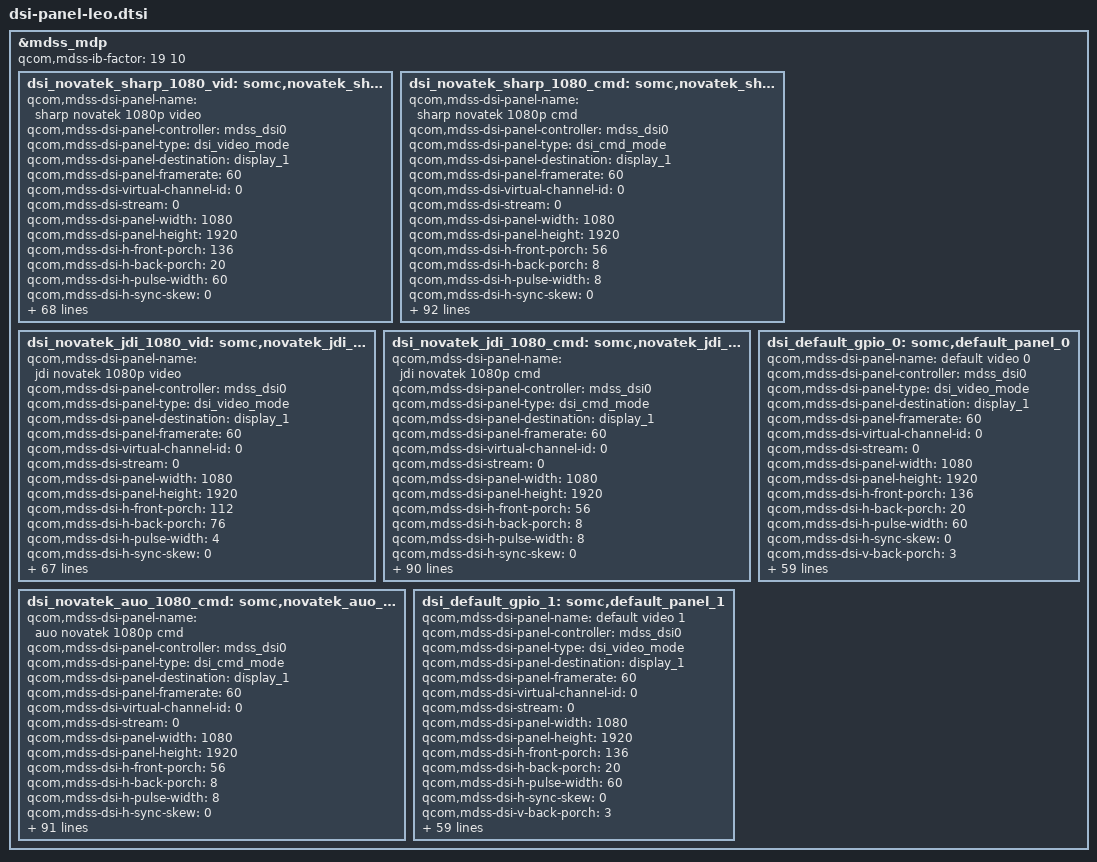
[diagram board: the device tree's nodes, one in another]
/* Copyright (c) 2012, Code Aurora Forum. All rights reserved.
 * Copyright (c) 2014 Sony Mobile Communications Inc.
 *
 * This program is free software; you can redistribute it and/or modify
 * it under the terms of the GNU General Public License version 2 and
 * only version 2 as published by the Free Software Foundation.
 *
 * This program is distributed in the hope that it will be useful,
 * but WITHOUT ANY WARRANTY; without even the implied warranty of
 * MERCHANTABILITY or FITNESS FOR A PARTICULAR PURPOSE.  See the
 * GNU General Public License for more details.
 */

&mdss_mdp {
	qcom,mdss-ib-factor = <19 10>;
	dsi_novatek_sharp_1080_vid: somc,novatek_sharp_1080p_video_panel {
		qcom,mdss-dsi-panel-name = "sharp novatek 1080p video";
		qcom,mdss-dsi-panel-controller = <&mdss_dsi0>;
		qcom,mdss-dsi-panel-type = "dsi_video_mode";
		qcom,mdss-dsi-panel-destination = "display_1";
		qcom,mdss-dsi-panel-framerate = <60>;
		qcom,mdss-dsi-virtual-channel-id = <0>;
		qcom,mdss-dsi-stream = <0>;
		qcom,mdss-dsi-panel-width = <1080>;
		qcom,mdss-dsi-panel-height = <1920>;
		qcom,mdss-dsi-h-front-porch = <136>;
		qcom,mdss-dsi-h-back-porch = <20>;
		qcom,mdss-dsi-h-pulse-width = <60>;
		qcom,mdss-dsi-h-sync-skew = <0>;
		qcom,mdss-dsi-v-back-porch = <3>;
		qcom,mdss-dsi-v-front-porch = <4>;
		qcom,mdss-dsi-v-pulse-width = <2>;
		qcom,mdss-dsi-h-left-border = <0>;
		qcom,mdss-dsi-h-right-border = <0>;
		qcom,mdss-dsi-v-top-border = <0>;
		qcom,mdss-dsi-v-bottom-border = <0>;
		qcom,mdss-dsi-bpp = <24>;
		qcom,mdss-dsi-underflow-color = <0x0>;
		qcom,mdss-dsi-border-color = <0>;
		somc,mdss-dsi-init-command = [15 01 00 00 00 00 02 BB 03
				39 01 00 00 00 00 06 3B 03 05 04 50 88
				15 01 00 00 00 00 02 FF 24
				15 01 00 00 00 00 02 FB 01
				15 01 00 00 00 00 02 C4 9A
				15 01 00 00 00 00 02 FF 10];
		qcom,mdss-dsi-on-command = [05 01 00 00 96 00 01 11
				05 01 00 00 28 00 01 29];
		qcom,mdss-dsi-off-command = [15 01 00 00 00 00 02 FF 10
				05 01 00 00 14 00 01 28
				05 01 00 00 50 00 01 10];
		qcom,mdss-dsi-on-command-state = "dsi_lp_mode";
		qcom,mdss-dsi-off-command-state = "dsi_hs_mode";
		qcom,mdss-dsi-h-sync-pulse = <1>;
		qcom,mdss-dsi-traffic-mode = "non_burst_sync_event";
		qcom,mdss-dsi-bllp-eof-power-mode;
		qcom,mdss-dsi-bllp-power-mode;
		qcom,mdss-dsi-lane-0-state;
		qcom,mdss-dsi-lane-1-state;
		qcom,mdss-dsi-lane-2-state;
		qcom,mdss-dsi-lane-3-state;
		qcom,mdss-dsi-panel-timings = [E6 38 26 00 68 6E 2A 3C 2C 03 04 00];
		qcom,mdss-dsi-lp11-init;
		qcom,mdss-dsi-t-clk-post = <0x02>;
		qcom,mdss-dsi-t-clk-pre = <0x2B>;
		qcom,mdss-dsi-bl-min-level = <1>;
		qcom,mdss-dsi-bl-max-level = <4095>;
		qcom,mdss-brightness-max-level = <4095>;
		qcom,mdss-dsi-dma-trigger = "trigger_sw";
		qcom,mdss-dsi-mdp-trigger = "none";
		qcom,mdss-dsi-bl-pmic-control-type = "bl_ctrl_wled";
		qcom,mdss-dsi-pan-enable-dynamic-fps;
		qcom,mdss-dsi-pan-fps-update = "dfps_suspend_resume_mode";
		qcom,cont-splash-enabled;

		somc,driver-ic = <0>;
		somc,dric-gpio = <&msmgpio 26 0>;
		somc,touch-reset-gpio = <&msmgpio 85 0>;
		somc,mul-channel-scaling = <3>;
		somc,mdss-phy-size-mm = <64 114>;
		somc,mdss-dsi-lane-config = [00 c2 ef 00 00 00 00 01 ff
				00 c2 ef 00 00 00 00 01 ff
				00 c2 ef 00 00 00 00 01 ff
				00 c2 ef 00 00 00 00 01 ff
				00 02 45 00 00 00 00 01 97];
		somc,mdss-dsi-disp-on-in-hs = <1>;
		somc,mdss-dsi-wait-time-before-on-cmd = <150>;
		somc,lcd-id = <1>;
		somc,lcd-id-adc = <215000 256000>;
		somc,disp-en-on-pre = <200>;
		somc,disp-en-on-post = <10>;
		somc,pw-on-rst-seq = <1 1>, <0 1>, <1 20>;
		somc,disp-en-off-post = <200>;
		somc,pw-off-rst-seq = <0 5>;
		somc,pw-down-period = <100>;

		somc,mdss-dsi-pre-uv-command = [23 01 00 00 00 00 02 B0 04];
		somc,mdss-dsi-uv-command = [06 01 00 00 00 00 01 DA
			06 01 00 00 00 00 01 DB];
		somc,mdss-dsi-uv-param-type = <4>;
		somc,mdss-dsi-pcc-table-size = <225>;
		somc,mdss-dsi-pcc-table = <
			0x00 0x01 0x38 0x3B 0x38 0x3B 0x5700 0x7000 0x8000
			0x00 0x02 0x34 0x37 0x38 0x3B 0x5900 0x6f00 0x8000
			0x00 0x03 0x30 0x33 0x38 0x3B 0x5c00 0x6e00 0x8000
			0x00 0x04 0x2C 0x2F 0x38 0x3B 0x5d80 0x6c80 0x8000
			0x00 0x05 0x28 0x2B 0x38 0x3B 0x6080 0x6c80 0x8000
			0x00 0x06 0x24 0x27 0x38 0x3B 0x6380 0x6c80 0x8000
			0x00 0x07 0x20 0x23 0x38 0x3B 0x6700 0x6c00 0x8000
			0x00 0x08 0x1C 0x1F 0x38 0x3B 0x6980 0x6b00 0x8000
			0x00 0x09 0x18 0x1B 0x38 0x3B 0x6d00 0x6a80 0x8000
			0x00 0x0A 0x14 0x17 0x38 0x3B 0x7180 0x6900 0x8000
			0x00 0x0B 0x10 0x13 0x38 0x3B 0x7800 0x6800 0x8000
			0x00 0x0C 0x0C 0x0F 0x38 0x3B 0x7d00 0x6700 0x8000
			0x00 0x0D 0x08 0x0B 0x38 0x3B 0x8000 0x6500 0x7d00
			0x00 0x0E 0x04 0x07 0x38 0x3B 0x8000 0x6000 0x7700
			0x00 0x0F 0x00 0x03 0x38 0x3B 0x8000 0x5900 0x7000
			0x00 0x10 0x38 0x3B 0x34 0x37 0x5900 0x7280 0x8000
			0x00 0x11 0x34 0x37 0x34 0x37 0x5b00 0x7100 0x8000
			0x00 0x12 0x30 0x33 0x34 0x37 0x5e00 0x7180 0x8000
			0x00 0x13 0x2C 0x2F 0x34 0x37 0x6080 0x7180 0x8000
			0x00 0x14 0x28 0x2B 0x34 0x37 0x6400 0x7000 0x8000
			0x00 0x15 0x24 0x27 0x34 0x37 0x6700 0x7000 0x8000
			0x00 0x16 0x20 0x23 0x34 0x37 0x6900 0x6f00 0x8000
			0x00 0x17 0x1C 0x1F 0x34 0x37 0x6c00 0x6e80 0x8000
			0x00 0x18 0x18 0x1B 0x34 0x37 0x7000 0x6d80 0x8000
			0x00 0x19 0x14 0x17 0x34 0x37 0x7580 0x6b80 0x8000
			0x00 0x1A 0x10 0x13 0x34 0x37 0x7b00 0x6a80 0x8000
			0x00 0x1B 0x0C 0x0F 0x34 0x37 0x8000 0x6a80 0x8000
			0x00 0x1C 0x08 0x0B 0x34 0x37 0x8000 0x6600 0x7c00
			0x00 0x1D 0x04 0x07 0x34 0x37 0x8000 0x6100 0x7400
			0x00 0x1E 0x00 0x03 0x34 0x37 0x8000 0x5b00 0x6e00
			0x00 0x1F 0x38 0x3B 0x30 0x33 0x5c80 0x7600 0x8000
			0x00 0x20 0x34 0x37 0x30 0x33 0x5e00 0x7500 0x8000
			0x00 0x21 0x30 0x33 0x30 0x33 0x6100 0x7480 0x8000
			0x00 0x22 0x2C 0x2F 0x30 0x33 0x6400 0x7400 0x8000
			0x00 0x23 0x28 0x2B 0x30 0x33 0x6500 0x7300 0x8000
			0x00 0x24 0x24 0x27 0x30 0x33 0x6880 0x7400 0x8000
			0x00 0x25 0x20 0x23 0x30 0x33 0x6b00 0x7200 0x8000
			0x00 0x26 0x1C 0x1F 0x30 0x33 0x6e00 0x6f00 0x8000
			0x00 0x27 0x18 0x1B 0x30 0x33 0x7300 0x7080 0x8000
			0x00 0x28 0x14 0x17 0x30 0x33 0x7700 0x6d80 0x8000
			0x00 0x29 0x10 0x13 0x30 0x33 0x7c00 0x6d80 0x8000
			0x00 0x2A 0x0C 0x0F 0x30 0x33 0x8000 0x6c00 0x7e00
			0x00 0x2B 0x08 0x0B 0x30 0x33 0x8000 0x6700 0x7a00
			0x00 0x2C 0x04 0x07 0x30 0x33 0x8000 0x6100 0x7200
			0x00 0x2D 0x00 0x03 0x30 0x33 0x8000 0x5b00 0x6c00
			0x00 0x2E 0x38 0x3B 0x2C 0x2F 0x5c00 0x7880 0x8000
			0x00 0x2F 0x34 0x37 0x2C 0x2F 0x5f00 0x7700 0x8000
			0x00 0x30 0x30 0x33 0x2C 0x2F 0x6100 0x7700 0x8000
			0x00 0x31 0x2C 0x2F 0x2C 0x2F 0x6500 0x7680 0x8000
			0x00 0x32 0x28 0x2B 0x2C 0x2F 0x6700 0x7600 0x8000
			0x00 0x33 0x24 0x27 0x2C 0x2F 0x6a00 0x7500 0x8000
			0x00 0x34 0x20 0x23 0x2C 0x2F 0x6e00 0x7500 0x8000
			0x00 0x35 0x1C 0x1F 0x2C 0x2F 0x7180 0x7400 0x8000
			0x00 0x36 0x18 0x1B 0x2C 0x2F 0x7580 0x7300 0x8000
			0x00 0x37 0x14 0x17 0x2C 0x2F 0x7b00 0x7080 0x8000
			0x00 0x38 0x10 0x13 0x2C 0x2F 0x8000 0x7080 0x7f00
			0x00 0x39 0x0C 0x0F 0x2C 0x2F 0x8000 0x6b00 0x7a00
			0x00 0x3A 0x08 0x0B 0x2C 0x2F 0x8000 0x6500 0x7400
			0x00 0x3B 0x04 0x07 0x2C 0x2F 0x8000 0x6000 0x6d00
			0x00 0x3C 0x00 0x03 0x2C 0x2F 0x8000 0x5a00 0x6800
			0x00 0x3D 0x38 0x3B 0x28 0x2B 0x6000 0x7c00 0x8000
			0x00 0x3E 0x34 0x37 0x28 0x2B 0x6200 0x7b00 0x8000
			0x00 0x3F 0x30 0x33 0x28 0x2B 0x6600 0x7b00 0x8000
			0x00 0x40 0x2C 0x2F 0x28 0x2B 0x6900 0x7c00 0x8000
			0x00 0x41 0x28 0x2B 0x28 0x2B 0x6b80 0x7900 0x8000
			0x00 0x42 0x24 0x27 0x28 0x2B 0x6e00 0x7900 0x8000
			0x00 0x43 0x20 0x23 0x28 0x2B 0x7100 0x7780 0x8000
			0x00 0x44 0x1C 0x1F 0x28 0x2B 0x7500 0x7700 0x8000
			0x00 0x45 0x18 0x1B 0x28 0x2B 0x7a00 0x7600 0x8000
			0x00 0x46 0x14 0x17 0x28 0x2B 0x8000 0x7500 0x8000
			0x00 0x47 0x10 0x13 0x28 0x2B 0x8000 0x7000 0x7c00
			0x00 0x48 0x0C 0x0F 0x28 0x2B 0x8000 0x6b00 0x7800
			0x00 0x49 0x08 0x0B 0x28 0x2B 0x8000 0x6600 0x7200
			0x00 0x4A 0x04 0x07 0x28 0x2B 0x8000 0x6000 0x6c00
			0x00 0x4B 0x00 0x03 0x28 0x2B 0x8000 0x5900 0x6500
			0x00 0x4C 0x38 0x3B 0x24 0x27 0x6200 0x8000 0x8000
			0x00 0x4D 0x34 0x37 0x24 0x27 0x6500 0x7f00 0x8000
			0x00 0x4E 0x30 0x33 0x24 0x27 0x6800 0x7f00 0x8000
			0x00 0x4F 0x2C 0x2F 0x24 0x27 0x6b00 0x7e00 0x8000
			0x00 0x50 0x28 0x2B 0x24 0x27 0x6e00 0x7c80 0x8000
			0x00 0x51 0x24 0x27 0x24 0x27 0x7200 0x7d00 0x8000
			0x00 0x52 0x20 0x23 0x24 0x27 0x7500 0x7a00 0x8000
			0x00 0x53 0x1C 0x1F 0x24 0x27 0x7900 0x7a00 0x8000
			0x00 0x54 0x18 0x1B 0x24 0x27 0x7e00 0x7a00 0x8000
			0x00 0x55 0x14 0x17 0x24 0x27 0x8000 0x7300 0x7c00
			0x00 0x56 0x10 0x13 0x24 0x27 0x8000 0x6e00 0x7800
			0x00 0x57 0x0C 0x0F 0x24 0x27 0x8000 0x6900 0x7300
			0x00 0x58 0x08 0x0B 0x24 0x27 0x8000 0x6400 0x6d00
			0x00 0x59 0x04 0x07 0x24 0x27 0x8000 0x5e00 0x6800
			0x00 0x5A 0x00 0x03 0x24 0x27 0x8000 0x5900 0x6300
			0x00 0x5B 0x38 0x3B 0x20 0x23 0x6200 0x8000 0x7d00
			0x00 0x5C 0x34 0x37 0x20 0x23 0x6600 0x8000 0x7e00
			0x00 0x5D 0x30 0x33 0x20 0x23 0x6a00 0x8000 0x7f00
			0x00 0x5E 0x2C 0x2F 0x20 0x23 0x6d00 0x8000 0x7f00
			0x00 0x5F 0x28 0x2B 0x20 0x23 0x7100 0x8000 0x8000
			0x00 0x60 0x24 0x27 0x20 0x23 0x7400 0x7f00 0x8000
			0x00 0x61 0x20 0x23 0x20 0x23 0x7700 0x7e80 0x8000
			0x00 0x62 0x1C 0x1F 0x20 0x23 0x7b00 0x7d00 0x8000
			0x00 0x63 0x18 0x1B 0x20 0x23 0x7f00 0x7c00 0x8000
			0x00 0x64 0x14 0x17 0x20 0x23 0x8000 0x7500 0x7b00
			0x00 0x65 0x10 0x13 0x20 0x23 0x8000 0x7000 0x7600
			0x00 0x66 0x0C 0x0F 0x20 0x23 0x8000 0x6a00 0x7100
			0x00 0x67 0x08 0x0B 0x20 0x23 0x8000 0x6400 0x6b00
			0x00 0x68 0x04 0x07 0x20 0x23 0x8000 0x5e00 0x6600
			0x00 0x69 0x00 0x03 0x20 0x23 0x8000 0x5800 0x6000
			0x00 0x6A 0x38 0x3B 0x1C 0x1F 0x6300 0x8000 0x7a00
			0x00 0x6B 0x34 0x37 0x1C 0x1F 0x6600 0x8000 0x7b00
			0x00 0x6C 0x30 0x33 0x1C 0x1F 0x6a00 0x8000 0x7c00
			0x00 0x6D 0x2C 0x2F 0x1C 0x1F 0x6e00 0x8000 0x7d00
			0x00 0x6E 0x28 0x2B 0x1C 0x1F 0x7200 0x8000 0x7e00
			0x00 0x6F 0x24 0x27 0x1C 0x1F 0x7600 0x8000 0x7e00
			0x00 0x70 0x20 0x23 0x1C 0x1F 0x7a00 0x8000 0x7f00
			0x00 0x71 0x18 0x1B 0x1C 0x1F 0x8000 0x7c00 0x7c00
			0x00 0x72 0x14 0x17 0x1C 0x1F 0x8000 0x7400 0x7780
			0x00 0x73 0x10 0x13 0x1C 0x1F 0x8000 0x6f00 0x7300
			0x00 0x74 0x0C 0x0F 0x1C 0x1F 0x8000 0x6900 0x6e00
			0x00 0x75 0x08 0x0B 0x1C 0x1F 0x8000 0x6300 0x6800
			0x00 0x76 0x04 0x07 0x1C 0x1F 0x8000 0x5d00 0x6280
			0x00 0x77 0x00 0x03 0x1C 0x1F 0x8000 0x5800 0x5d00
			0x00 0x78 0x38 0x3B 0x18 0x1B 0x6300 0x8000 0x7800
			0x00 0x79 0x34 0x37 0x18 0x1B 0x6700 0x8000 0x7900
			0x00 0x7A 0x30 0x33 0x18 0x1B 0x6a00 0x8000 0x7900
			0x00 0x7B 0x2C 0x2F 0x18 0x1B 0x6e00 0x8000 0x7b00
			0x00 0x7C 0x28 0x2B 0x18 0x1B 0x7180 0x8000 0x7c00
			0x00 0x7D 0x24 0x27 0x18 0x1B 0x7500 0x8000 0x7b00
			0x00 0x7E 0x20 0x23 0x18 0x1B 0x7a00 0x8000 0x7c80
			0x00 0x7F 0x1C 0x1F 0x18 0x1B 0x8000 0x8000 0x7e00
			0x00 0x80 0x18 0x1B 0x18 0x1B 0x8000 0x7a00 0x7900
			0x00 0x81 0x14 0x17 0x18 0x1B 0x8000 0x7400 0x7500
			0x00 0x82 0x10 0x13 0x18 0x1B 0x8000 0x6e00 0x6f00
			0x00 0x83 0x0C 0x0F 0x18 0x1B 0x8000 0x6900 0x6b00
			0x00 0x84 0x08 0x0B 0x18 0x1B 0x8000 0x6200 0x6500
			0x00 0x85 0x04 0x07 0x18 0x1B 0x8000 0x5d00 0x6000
			0x00 0x86 0x00 0x03 0x18 0x1B 0x8000 0x5700 0x5b00
			0x00 0x87 0x38 0x3B 0x14 0x17 0x6300 0x8000 0x7580
			0x00 0x88 0x34 0x37 0x14 0x17 0x6700 0x8000 0x7680
			0x00 0x89 0x30 0x33 0x14 0x17 0x6a00 0x8000 0x7780
			0x00 0x8A 0x2C 0x2F 0x14 0x17 0x6d00 0x8000 0x7800
			0x00 0x8B 0x28 0x2B 0x14 0x17 0x7100 0x8000 0x7800
			0x00 0x8C 0x24 0x27 0x14 0x17 0x7500 0x8000 0x7980
			0x00 0x8D 0x20 0x23 0x14 0x17 0x7a00 0x8000 0x7a00
			0x00 0x8E 0x1C 0x1F 0x14 0x17 0x7f00 0x8000 0x7a80
			0x00 0x8F 0x18 0x1B 0x14 0x17 0x8000 0x7b00 0x7700
			0x00 0x90 0x14 0x17 0x14 0x17 0x8000 0x7300 0x7100
			0x00 0x91 0x10 0x13 0x14 0x17 0x8000 0x6d00 0x6d00
			0x00 0x92 0x0C 0x0F 0x14 0x17 0x8000 0x6800 0x6900
			0x00 0x93 0x08 0x0B 0x14 0x17 0x8000 0x6200 0x6300
			0x00 0x94 0x04 0x07 0x14 0x17 0x8000 0x5c00 0x5d00
			0x00 0x95 0x00 0x03 0x14 0x17 0x8000 0x5600 0x5900
			0x00 0x96 0x38 0x3B 0x10 0x13 0x6300 0x8000 0x7300
			0x00 0x97 0x34 0x37 0x10 0x13 0x6600 0x8000 0x7400
			0x00 0x98 0x30 0x33 0x10 0x13 0x6a00 0x8000 0x7500
			0x00 0x99 0x2C 0x2F 0x10 0x13 0x6e00 0x8000 0x7600
			0x00 0x9A 0x28 0x2B 0x10 0x13 0x7100 0x8000 0x7600
			0x00 0x9B 0x24 0x27 0x10 0x13 0x7500 0x8000 0x7700
			0x00 0x9C 0x20 0x23 0x10 0x13 0x7980 0x8000 0x7800
			0x00 0x9D 0x1C 0x1F 0x10 0x13 0x7f00 0x8000 0x7800
			0x00 0x9E 0x18 0x1B 0x10 0x13 0x8000 0x7b00 0x7500
			0x00 0x9F 0x14 0x17 0x10 0x13 0x8000 0x7300 0x6f00
			0x00 0xA0 0x10 0x13 0x10 0x13 0x8000 0x6d00 0x6b00
			0x00 0xA1 0x0C 0x0F 0x10 0x13 0x8000 0x6800 0x6600
			0x00 0xA2 0x08 0x0B 0x10 0x13 0x8000 0x6200 0x6000
			0x00 0xA3 0x04 0x07 0x10 0x13 0x8000 0x5b00 0x5b00
			0x00 0xA4 0x00 0x03 0x10 0x13 0x8000 0x5600 0x5700
			0x00 0xA5 0x38 0x3B 0x0C 0x0F 0x6200 0x8000 0x7000
			0x00 0xA6 0x34 0x37 0x0C 0x0F 0x6700 0x8000 0x7100
			0x00 0xA7 0x30 0x33 0x0C 0x0F 0x6a00 0x8000 0x7200
			0x00 0xA8 0x2C 0x2F 0x0C 0x0F 0x6d00 0x8000 0x7300
			0x00 0xA9 0x28 0x2B 0x0C 0x0F 0x7100 0x8000 0x7400
			0x00 0xAA 0x24 0x27 0x0C 0x0F 0x7500 0x8000 0x7480
			0x00 0xAB 0x20 0x23 0x0C 0x0F 0x7900 0x8000 0x7500
			0x00 0xAC 0x1C 0x1F 0x0C 0x0F 0x7f00 0x8000 0x7600
			0x00 0xAD 0x18 0x1B 0x0C 0x0F 0x8000 0x7b00 0x7200
			0x00 0xAE 0x14 0x17 0x0C 0x0F 0x8000 0x7300 0x6d00
			0x00 0xAF 0x10 0x13 0x0C 0x0F 0x8000 0x6d00 0x6800
			0x00 0xB0 0x0C 0x0F 0x0C 0x0F 0x8000 0x6800 0x6400
			0x00 0xB1 0x08 0x0B 0x0C 0x0F 0x8000 0x6100 0x5d00
			0x00 0xB2 0x04 0x07 0x0C 0x0F 0x8000 0x5b00 0x5900
			0x00 0xB3 0x00 0x03 0x0C 0x0F 0x8000 0x5600 0x5480
			0x00 0xB4 0x38 0x3B 0x08 0x0B 0x6200 0x8000 0x6e00
			0x00 0xB5 0x34 0x37 0x08 0x0B 0x6600 0x8000 0x6e00
			0x00 0xB6 0x30 0x33 0x08 0x0B 0x6900 0x8000 0x6f00
			0x00 0xB7 0x2C 0x2F 0x08 0x0B 0x6d00 0x8000 0x7000
			0x00 0xB8 0x28 0x2B 0x08 0x0B 0x7100 0x8000 0x7200
			0x00 0xB9 0x24 0x27 0x08 0x0B 0x7500 0x8000 0x7200
			0x00 0xBA 0x20 0x23 0x08 0x0B 0x7a00 0x8000 0x7200
			0x00 0xBB 0x1C 0x1F 0x08 0x0B 0x7f00 0x8000 0x7300
			0x00 0xBC 0x18 0x1B 0x08 0x0B 0x8000 0x7b00 0x7000
			0x00 0xBD 0x14 0x17 0x08 0x0B 0x8000 0x7200 0x6a00
			0x00 0xBE 0x10 0x13 0x08 0x0B 0x8000 0x6c00 0x6500
			0x00 0xBF 0x0C 0x0F 0x08 0x0B 0x8000 0x6600 0x6000
			0x00 0xC0 0x08 0x0B 0x08 0x0B 0x8000 0x6000 0x5b00
			0x00 0xC1 0x04 0x07 0x08 0x0B 0x8000 0x5b00 0x5700
			0x00 0xC2 0x00 0x03 0x08 0x0B 0x8000 0x5500 0x5100
			0x00 0xC3 0x38 0x3B 0x04 0x07 0x6200 0x8000 0x6b00
			0x00 0xC4 0x34 0x37 0x04 0x07 0x6500 0x8000 0x6c00
			0x00 0xC5 0x30 0x33 0x04 0x07 0x6800 0x8000 0x6d80
			0x00 0xC6 0x2C 0x2F 0x04 0x07 0x6c00 0x8000 0x6e00
			0x00 0xC7 0x28 0x2B 0x04 0x07 0x7000 0x8000 0x6e00
			0x00 0xC8 0x24 0x27 0x04 0x07 0x7400 0x8000 0x6f00
			0x00 0xC9 0x20 0x23 0x04 0x07 0x7800 0x8000 0x7000
			0x00 0xCA 0x1C 0x1F 0x04 0x07 0x7e00 0x8000 0x7000
			0x00 0xCB 0x18 0x1B 0x04 0x07 0x8000 0x7a80 0x6b80
			0x00 0xCC 0x14 0x17 0x04 0x07 0x8000 0x7400 0x6780
			0x00 0xCD 0x10 0x13 0x04 0x07 0x8000 0x6e00 0x6380
			0x00 0xCE 0x0C 0x0F 0x04 0x07 0x8000 0x6700 0x5e00
			0x00 0xCF 0x08 0x0B 0x04 0x07 0x8000 0x6180 0x5980
			0x00 0xD0 0x04 0x07 0x04 0x07 0x8000 0x5b00 0x5500
			0x00 0xD1 0x00 0x03 0x04 0x07 0x8000 0x5500 0x5100
			0x00 0xD2 0x38 0x3B 0x00 0x03 0x6100 0x8000 0x6900
			0x00 0xD3 0x34 0x37 0x00 0x03 0x6400 0x8000 0x6a00
			0x00 0xD4 0x30 0x33 0x00 0x03 0x6800 0x8000 0x6b00
			0x00 0xD5 0x2C 0x2F 0x00 0x03 0x6c00 0x8000 0x6b80
			0x00 0xD6 0x28 0x2B 0x00 0x03 0x6f00 0x8000 0x6c00
			0x00 0xD7 0x24 0x27 0x00 0x03 0x7300 0x8000 0x6d00
			0x00 0xD8 0x20 0x23 0x00 0x03 0x7900 0x8000 0x6d00
			0x00 0xD9 0x1C 0x1F 0x00 0x03 0x7f00 0x8000 0x6e00
			0x00 0xDA 0x18 0x1B 0x00 0x03 0x8000 0x7b00 0x6a80
			0x00 0xDB 0x14 0x17 0x00 0x03 0x8000 0x7400 0x6580
			0x00 0xDC 0x10 0x13 0x00 0x03 0x8000 0x6d00 0x6180
			0x00 0xDD 0x0C 0x0F 0x00 0x03 0x8000 0x6900 0x5e00
			0x00 0xDE 0x08 0x0B 0x00 0x03 0x8000 0x6200 0x5800
			0x00 0xDF 0x04 0x07 0x00 0x03 0x8000 0x5a00 0x5200
			0x00 0xE0 0x00 0x03 0x00 0x03 0x8000 0x5400 0x4d00
			0xFF 0x00 0x00 0x3B 0x00 0x3B 0x8000 0x8000 0x8000>;
	};

	dsi_novatek_sharp_1080_cmd: somc,novatek_sharp_1080p_cmd_panel {
		qcom,mdss-dsi-panel-name = "sharp novatek 1080p cmd";
		qcom,mdss-dsi-panel-controller = <&mdss_dsi0>;
		qcom,mdss-dsi-panel-type = "dsi_cmd_mode";
		qcom,mdss-dsi-panel-destination = "display_1";
		qcom,mdss-dsi-panel-framerate = <60>;
		qcom,mdss-dsi-virtual-channel-id = <0>;
		qcom,mdss-dsi-stream = <0>;
		qcom,mdss-dsi-panel-width = <1080>;
		qcom,mdss-dsi-panel-height = <1920>;
		qcom,mdss-dsi-h-front-porch = <56>;
		qcom,mdss-dsi-h-back-porch = <8>;
		qcom,mdss-dsi-h-pulse-width = <8>;
		qcom,mdss-dsi-h-sync-skew = <0>;
		qcom,mdss-dsi-v-back-porch = <4>;
		qcom,mdss-dsi-v-front-porch = <237>;
		qcom,mdss-dsi-v-pulse-width = <2>;
		qcom,mdss-dsi-h-left-border = <0>;
		qcom,mdss-dsi-h-right-border = <0>;
		qcom,mdss-dsi-v-top-border = <0>;
		qcom,mdss-dsi-v-bottom-border = <0>;
		qcom,mdss-dsi-bpp = <24>;
		qcom,mdss-dsi-underflow-color = <0x0>;
		qcom,mdss-dsi-border-color = <0>;
		somc,mdss-dsi-init-command = [15 01 00 00 00 00 02 BB 10
				15 01 00 00 00 00 02 FF 24
				15 01 00 00 00 00 02 FB 01
				15 01 00 00 00 00 02 C4 9A
				15 01 00 00 00 00 02 85 05
				15 01 00 00 00 00 02 93 02
				15 01 00 00 00 00 02 94 08
				15 01 00 00 00 00 02 92 95
				15 01 00 00 00 00 02 FF 10
				15 01 00 00 00 00 02 FF 20
				15 01 00 00 00 00 02 FB 01
				15 01 00 00 00 00 02 58 82
				15 01 00 00 00 00 02 59 02
				15 01 00 00 00 00 02 5A 02
				15 01 00 00 00 00 02 5B 02
				15 01 00 00 00 00 02 5C 83
				15 01 00 00 00 00 02 5D 83
				15 01 00 00 00 00 02 5E 03
				15 01 00 00 00 00 02 5F 03
				15 01 00 00 00 00 02 6D 55
				15 01 00 00 00 00 02 FF 10
				15 01 00 00 00 00 02 FF 24
				15 01 00 00 00 00 02 FB 01
				15 01 00 00 00 00 02 C4 02
				15 01 00 00 00 00 02 FF 10
				15 01 00 00 00 00 02 35 00
				39 01 00 00 00 00 03 44 03 00
				05 01 00 00 1E 00 01 11];
		qcom,mdss-dsi-on-command = [05 01 00 00 28 00 01 29];
		qcom,mdss-dsi-off-command = [15 01 00 00 00 00 02 FF 10
				05 01 00 00 14 00 01 28
				05 01 00 00 50 00 01 10];
		qcom,mdss-dsi-on-command-state = "dsi_hs_mode";
		qcom,mdss-dsi-off-command-state = "dsi_hs_mode";

		qcom,mdss-dsi-h-sync-pulse = <1>;
		qcom,mdss-dsi-traffic-mode = "non_burst_sync_event";
		qcom,mdss-dsi-bllp-eof-power-mode;
		qcom,mdss-dsi-bllp-power-mode;
		qcom,mdss-dsi-lane-0-state;
		qcom,mdss-dsi-lane-1-state;
		qcom,mdss-dsi-lane-2-state;
		qcom,mdss-dsi-lane-3-state;
		qcom,mdss-dsi-te-pin-select = <1>;
		qcom,mdss-dsi-wr-mem-start = <0x2c>;
		qcom,mdss-dsi-wr-mem-continue = <0x3c>;
		qcom,mdss-dsi-te-dcs-command = <1>;
		qcom,mdss-dsi-te-check-enable;
		qcom,mdss-dsi-te-using-te-pin;
		qcom,mdss-dsi-panel-timings = [E6 38 26 00 68 6E 2A 3C 2C 03 04 00];
		qcom,mdss-dsi-lp11-init;
		qcom,mdss-dsi-t-clk-post = <0x21>;
		qcom,mdss-dsi-t-clk-pre = <0x2B>;
		qcom,mdss-dsi-bl-min-level = <1>;
		qcom,mdss-dsi-bl-max-level = <4095>;
		qcom,mdss-brightness-max-level = <4095>;
		qcom,mdss-dsi-dma-trigger = "trigger_sw";
		qcom,mdss-dsi-mdp-trigger = "none";
		qcom,mdss-dsi-bl-pmic-control-type = "bl_ctrl_wled";
		qcom,mdss-dsi-pan-enable-dynamic-fps;
		qcom,mdss-dsi-pan-fps-update = "dfps_suspend_resume_mode";
		qcom,cont-splash-enabled;

		somc,driver-ic = <0>;
		somc,dric-gpio = <&msmgpio 26 0>;
		somc,touch-reset-gpio = <&msmgpio 85 0>;
		somc,mul-channel-scaling = <3>;
		somc,mdss-phy-size-mm = <64 114>;
		somc,mdss-dsi-lane-config = [00 c2 ef 00 00 00 00 01 ff
				00 c2 ef 00 00 00 00 01 ff
				00 c2 ef 00 00 00 00 01 ff
				00 c2 ef 00 00 00 00 01 ff
				00 02 45 00 00 00 00 01 97];
		somc,mdss-dsi-disp-on-in-hs = <0>;
		somc,mdss-dsi-wait-time-before-on-cmd = <150>;
		somc,lcd-id = <1>;
		somc,lcd-id-adc = <0 57000>;
		somc,disp-en-on-pre = <10>;
		somc,disp-en-on-post = <20>;
		somc,pw-on-rst-seq = <1 1>, <0 1>, <1 20>;
		somc,disp-en-off-post = <200>;
		somc,pw-off-rst-seq = <0 5>;
		somc,pw-down-period = <100>;

		somc,mdss-dsi-pre-uv-command = [23 01 00 00 00 00 02 B0 04];
		somc,mdss-dsi-uv-command = [06 01 00 00 00 00 01 DA
			06 01 00 00 00 00 01 DB];
		somc,mdss-dsi-uv-param-type = <4>;
		somc,mdss-dsi-pcc-table-size = <225>;
		somc,mdss-dsi-pcc-table = <
			0x00 0x01 0x38 0x3B 0x38 0x3B 0x5700 0x7000 0x8000
			0x00 0x02 0x34 0x37 0x38 0x3B 0x5900 0x6f00 0x8000
			0x00 0x03 0x30 0x33 0x38 0x3B 0x5c00 0x6e00 0x8000
			0x00 0x04 0x2C 0x2F 0x38 0x3B 0x5d80 0x6c80 0x8000
			0x00 0x05 0x28 0x2B 0x38 0x3B 0x6080 0x6c80 0x8000
			0x00 0x06 0x24 0x27 0x38 0x3B 0x6380 0x6c80 0x8000
			0x00 0x07 0x20 0x23 0x38 0x3B 0x6700 0x6c00 0x8000
			0x00 0x08 0x1C 0x1F 0x38 0x3B 0x6980 0x6b00 0x8000
			0x00 0x09 0x18 0x1B 0x38 0x3B 0x6d00 0x6a80 0x8000
			0x00 0x0A 0x14 0x17 0x38 0x3B 0x7180 0x6900 0x8000
			0x00 0x0B 0x10 0x13 0x38 0x3B 0x7800 0x6800 0x8000
			0x00 0x0C 0x0C 0x0F 0x38 0x3B 0x7d00 0x6700 0x8000
			0x00 0x0D 0x08 0x0B 0x38 0x3B 0x8000 0x6500 0x7d00
			0x00 0x0E 0x04 0x07 0x38 0x3B 0x8000 0x6000 0x7700
			0x00 0x0F 0x00 0x03 0x38 0x3B 0x8000 0x5900 0x7000
			0x00 0x10 0x38 0x3B 0x34 0x37 0x5900 0x7280 0x8000
			0x00 0x11 0x34 0x37 0x34 0x37 0x5b00 0x7100 0x8000
			0x00 0x12 0x30 0x33 0x34 0x37 0x5e00 0x7180 0x8000
			0x00 0x13 0x2C 0x2F 0x34 0x37 0x6080 0x7180 0x8000
			0x00 0x14 0x28 0x2B 0x34 0x37 0x6400 0x7000 0x8000
			0x00 0x15 0x24 0x27 0x34 0x37 0x6700 0x7000 0x8000
			0x00 0x16 0x20 0x23 0x34 0x37 0x6900 0x6f00 0x8000
			0x00 0x17 0x1C 0x1F 0x34 0x37 0x6c00 0x6e80 0x8000
			0x00 0x18 0x18 0x1B 0x34 0x37 0x7000 0x6d80 0x8000
			0x00 0x19 0x14 0x17 0x34 0x37 0x7580 0x6b80 0x8000
			0x00 0x1A 0x10 0x13 0x34 0x37 0x7b00 0x6a80 0x8000
			0x00 0x1B 0x0C 0x0F 0x34 0x37 0x8000 0x6a80 0x8000
			0x00 0x1C 0x08 0x0B 0x34 0x37 0x8000 0x6600 0x7c00
			0x00 0x1D 0x04 0x07 0x34 0x37 0x8000 0x6100 0x7400
			0x00 0x1E 0x00 0x03 0x34 0x37 0x8000 0x5b00 0x6e00
			0x00 0x1F 0x38 0x3B 0x30 0x33 0x5c80 0x7600 0x8000
			0x00 0x20 0x34 0x37 0x30 0x33 0x5e00 0x7500 0x8000
			0x00 0x21 0x30 0x33 0x30 0x33 0x6100 0x7480 0x8000
			0x00 0x22 0x2C 0x2F 0x30 0x33 0x6400 0x7400 0x8000
			0x00 0x23 0x28 0x2B 0x30 0x33 0x6500 0x7300 0x8000
			0x00 0x24 0x24 0x27 0x30 0x33 0x6880 0x7400 0x8000
			0x00 0x25 0x20 0x23 0x30 0x33 0x6b00 0x7200 0x8000
			0x00 0x26 0x1C 0x1F 0x30 0x33 0x6e00 0x6f00 0x8000
			0x00 0x27 0x18 0x1B 0x30 0x33 0x7300 0x7080 0x8000
			0x00 0x28 0x14 0x17 0x30 0x33 0x7700 0x6d80 0x8000
			0x00 0x29 0x10 0x13 0x30 0x33 0x7c00 0x6d80 0x8000
			0x00 0x2A 0x0C 0x0F 0x30 0x33 0x8000 0x6c00 0x7e00
			0x00 0x2B 0x08 0x0B 0x30 0x33 0x8000 0x6700 0x7a00
			0x00 0x2C 0x04 0x07 0x30 0x33 0x8000 0x6100 0x7200
			0x00 0x2D 0x00 0x03 0x30 0x33 0x8000 0x5b00 0x6c00
			0x00 0x2E 0x38 0x3B 0x2C 0x2F 0x5c00 0x7880 0x8000
			0x00 0x2F 0x34 0x37 0x2C 0x2F 0x5f00 0x7700 0x8000
			0x00 0x30 0x30 0x33 0x2C 0x2F 0x6100 0x7700 0x8000
			0x00 0x31 0x2C 0x2F 0x2C 0x2F 0x6500 0x7680 0x8000
			0x00 0x32 0x28 0x2B 0x2C 0x2F 0x6700 0x7600 0x8000
			0x00 0x33 0x24 0x27 0x2C 0x2F 0x6a00 0x7500 0x8000
			0x00 0x34 0x20 0x23 0x2C 0x2F 0x6e00 0x7500 0x8000
			0x00 0x35 0x1C 0x1F 0x2C 0x2F 0x7180 0x7400 0x8000
			0x00 0x36 0x18 0x1B 0x2C 0x2F 0x7580 0x7300 0x8000
			0x00 0x37 0x14 0x17 0x2C 0x2F 0x7b00 0x7080 0x8000
			0x00 0x38 0x10 0x13 0x2C 0x2F 0x8000 0x7080 0x7f00
			0x00 0x39 0x0C 0x0F 0x2C 0x2F 0x8000 0x6b00 0x7a00
			0x00 0x3A 0x08 0x0B 0x2C 0x2F 0x8000 0x6500 0x7400
			0x00 0x3B 0x04 0x07 0x2C 0x2F 0x8000 0x6000 0x6d00
			0x00 0x3C 0x00 0x03 0x2C 0x2F 0x8000 0x5a00 0x6800
			0x00 0x3D 0x38 0x3B 0x28 0x2B 0x6000 0x7c00 0x8000
			0x00 0x3E 0x34 0x37 0x28 0x2B 0x6200 0x7b00 0x8000
			0x00 0x3F 0x30 0x33 0x28 0x2B 0x6600 0x7b00 0x8000
			0x00 0x40 0x2C 0x2F 0x28 0x2B 0x6900 0x7c00 0x8000
			0x00 0x41 0x28 0x2B 0x28 0x2B 0x6b80 0x7900 0x8000
			0x00 0x42 0x24 0x27 0x28 0x2B 0x6e00 0x7900 0x8000
			0x00 0x43 0x20 0x23 0x28 0x2B 0x7100 0x7780 0x8000
			0x00 0x44 0x1C 0x1F 0x28 0x2B 0x7500 0x7700 0x8000
			0x00 0x45 0x18 0x1B 0x28 0x2B 0x7a00 0x7600 0x8000
			0x00 0x46 0x14 0x17 0x28 0x2B 0x8000 0x7500 0x8000
			0x00 0x47 0x10 0x13 0x28 0x2B 0x8000 0x7000 0x7c00
			0x00 0x48 0x0C 0x0F 0x28 0x2B 0x8000 0x6b00 0x7800
			0x00 0x49 0x08 0x0B 0x28 0x2B 0x8000 0x6600 0x7200
			0x00 0x4A 0x04 0x07 0x28 0x2B 0x8000 0x6000 0x6c00
			0x00 0x4B 0x00 0x03 0x28 0x2B 0x8000 0x5900 0x6500
			0x00 0x4C 0x38 0x3B 0x24 0x27 0x6200 0x8000 0x8000
			0x00 0x4D 0x34 0x37 0x24 0x27 0x6500 0x7f00 0x8000
			0x00 0x4E 0x30 0x33 0x24 0x27 0x6800 0x7f00 0x8000
			0x00 0x4F 0x2C 0x2F 0x24 0x27 0x6b00 0x7e00 0x8000
			0x00 0x50 0x28 0x2B 0x24 0x27 0x6e00 0x7c80 0x8000
			0x00 0x51 0x24 0x27 0x24 0x27 0x7200 0x7d00 0x8000
			0x00 0x52 0x20 0x23 0x24 0x27 0x7500 0x7a00 0x8000
			0x00 0x53 0x1C 0x1F 0x24 0x27 0x7900 0x7a00 0x8000
			0x00 0x54 0x18 0x1B 0x24 0x27 0x7e00 0x7a00 0x8000
			0x00 0x55 0x14 0x17 0x24 0x27 0x8000 0x7300 0x7c00
			0x00 0x56 0x10 0x13 0x24 0x27 0x8000 0x6e00 0x7800
			0x00 0x57 0x0C 0x0F 0x24 0x27 0x8000 0x6900 0x7300
			0x00 0x58 0x08 0x0B 0x24 0x27 0x8000 0x6400 0x6d00
			0x00 0x59 0x04 0x07 0x24 0x27 0x8000 0x5e00 0x6800
			0x00 0x5A 0x00 0x03 0x24 0x27 0x8000 0x5900 0x6300
			0x00 0x5B 0x38 0x3B 0x20 0x23 0x6200 0x8000 0x7d00
			0x00 0x5C 0x34 0x37 0x20 0x23 0x6600 0x8000 0x7e00
			0x00 0x5D 0x30 0x33 0x20 0x23 0x6a00 0x8000 0x7f00
			0x00 0x5E 0x2C 0x2F 0x20 0x23 0x6d00 0x8000 0x7f00
			0x00 0x5F 0x28 0x2B 0x20 0x23 0x7100 0x8000 0x8000
			0x00 0x60 0x24 0x27 0x20 0x23 0x7400 0x7f00 0x8000
			0x00 0x61 0x20 0x23 0x20 0x23 0x7700 0x7e80 0x8000
			0x00 0x62 0x1C 0x1F 0x20 0x23 0x7b00 0x7d00 0x8000
			0x00 0x63 0x18 0x1B 0x20 0x23 0x7f00 0x7c00 0x8000
			0x00 0x64 0x14 0x17 0x20 0x23 0x8000 0x7500 0x7b00
			0x00 0x65 0x10 0x13 0x20 0x23 0x8000 0x7000 0x7600
			0x00 0x66 0x0C 0x0F 0x20 0x23 0x8000 0x6a00 0x7100
			0x00 0x67 0x08 0x0B 0x20 0x23 0x8000 0x6400 0x6b00
			0x00 0x68 0x04 0x07 0x20 0x23 0x8000 0x5e00 0x6600
			0x00 0x69 0x00 0x03 0x20 0x23 0x8000 0x5800 0x6000
			0x00 0x6A 0x38 0x3B 0x1C 0x1F 0x6300 0x8000 0x7a00
			0x00 0x6B 0x34 0x37 0x1C 0x1F 0x6600 0x8000 0x7b00
			0x00 0x6C 0x30 0x33 0x1C 0x1F 0x6a00 0x8000 0x7c00
			0x00 0x6D 0x2C 0x2F 0x1C 0x1F 0x6e00 0x8000 0x7d00
			0x00 0x6E 0x28 0x2B 0x1C 0x1F 0x7200 0x8000 0x7e00
			0x00 0x6F 0x24 0x27 0x1C 0x1F 0x7600 0x8000 0x7e00
			0x00 0x70 0x20 0x23 0x1C 0x1F 0x7a00 0x8000 0x7f00
			0x00 0x71 0x18 0x1B 0x1C 0x1F 0x8000 0x7c00 0x7c00
			0x00 0x72 0x14 0x17 0x1C 0x1F 0x8000 0x7400 0x7780
			0x00 0x73 0x10 0x13 0x1C 0x1F 0x8000 0x6f00 0x7300
			0x00 0x74 0x0C 0x0F 0x1C 0x1F 0x8000 0x6900 0x6e00
			0x00 0x75 0x08 0x0B 0x1C 0x1F 0x8000 0x6300 0x6800
			0x00 0x76 0x04 0x07 0x1C 0x1F 0x8000 0x5d00 0x6280
			0x00 0x77 0x00 0x03 0x1C 0x1F 0x8000 0x5800 0x5d00
			0x00 0x78 0x38 0x3B 0x18 0x1B 0x6300 0x8000 0x7800
			0x00 0x79 0x34 0x37 0x18 0x1B 0x6700 0x8000 0x7900
			0x00 0x7A 0x30 0x33 0x18 0x1B 0x6a00 0x8000 0x7900
			0x00 0x7B 0x2C 0x2F 0x18 0x1B 0x6e00 0x8000 0x7b00
			0x00 0x7C 0x28 0x2B 0x18 0x1B 0x7180 0x8000 0x7c00
			0x00 0x7D 0x24 0x27 0x18 0x1B 0x7500 0x8000 0x7b00
			0x00 0x7E 0x20 0x23 0x18 0x1B 0x7a00 0x8000 0x7c80
			0x00 0x7F 0x1C 0x1F 0x18 0x1B 0x8000 0x8000 0x7e00
			0x00 0x80 0x18 0x1B 0x18 0x1B 0x8000 0x7a00 0x7900
			0x00 0x81 0x14 0x17 0x18 0x1B 0x8000 0x7400 0x7500
			0x00 0x82 0x10 0x13 0x18 0x1B 0x8000 0x6e00 0x6f00
			0x00 0x83 0x0C 0x0F 0x18 0x1B 0x8000 0x6900 0x6b00
			0x00 0x84 0x08 0x0B 0x18 0x1B 0x8000 0x6200 0x6500
			0x00 0x85 0x04 0x07 0x18 0x1B 0x8000 0x5d00 0x6000
			0x00 0x86 0x00 0x03 0x18 0x1B 0x8000 0x5700 0x5b00
			0x00 0x87 0x38 0x3B 0x14 0x17 0x6300 0x8000 0x7580
			0x00 0x88 0x34 0x37 0x14 0x17 0x6700 0x8000 0x7680
			0x00 0x89 0x30 0x33 0x14 0x17 0x6a00 0x8000 0x7780
			0x00 0x8A 0x2C 0x2F 0x14 0x17 0x6d00 0x8000 0x7800
			0x00 0x8B 0x28 0x2B 0x14 0x17 0x7100 0x8000 0x7800
			0x00 0x8C 0x24 0x27 0x14 0x17 0x7500 0x8000 0x7980
			0x00 0x8D 0x20 0x23 0x14 0x17 0x7a00 0x8000 0x7a00
			0x00 0x8E 0x1C 0x1F 0x14 0x17 0x7f00 0x8000 0x7a80
			0x00 0x8F 0x18 0x1B 0x14 0x17 0x8000 0x7b00 0x7700
			0x00 0x90 0x14 0x17 0x14 0x17 0x8000 0x7300 0x7100
			0x00 0x91 0x10 0x13 0x14 0x17 0x8000 0x6d00 0x6d00
			0x00 0x92 0x0C 0x0F 0x14 0x17 0x8000 0x6800 0x6900
			0x00 0x93 0x08 0x0B 0x14 0x17 0x8000 0x6200 0x6300
			0x00 0x94 0x04 0x07 0x14 0x17 0x8000 0x5c00 0x5d00
			0x00 0x95 0x00 0x03 0x14 0x17 0x8000 0x5600 0x5900
			0x00 0x96 0x38 0x3B 0x10 0x13 0x6300 0x8000 0x7300
			0x00 0x97 0x34 0x37 0x10 0x13 0x6600 0x8000 0x7400
			0x00 0x98 0x30 0x33 0x10 0x13 0x6a00 0x8000 0x7500
			0x00 0x99 0x2C 0x2F 0x10 0x13 0x6e00 0x8000 0x7600
			0x00 0x9A 0x28 0x2B 0x10 0x13 0x7100 0x8000 0x7600
			0x00 0x9B 0x24 0x27 0x10 0x13 0x7500 0x8000 0x7700
			0x00 0x9C 0x20 0x23 0x10 0x13 0x7980 0x8000 0x7800
			0x00 0x9D 0x1C 0x1F 0x10 0x13 0x7f00 0x8000 0x7800
			0x00 0x9E 0x18 0x1B 0x10 0x13 0x8000 0x7b00 0x7500
			0x00 0x9F 0x14 0x17 0x10 0x13 0x8000 0x7300 0x6f00
			0x00 0xA0 0x10 0x13 0x10 0x13 0x8000 0x6d00 0x6b00
			0x00 0xA1 0x0C 0x0F 0x10 0x13 0x8000 0x6800 0x6600
			0x00 0xA2 0x08 0x0B 0x10 0x13 0x8000 0x6200 0x6000
			0x00 0xA3 0x04 0x07 0x10 0x13 0x8000 0x5b00 0x5b00
			0x00 0xA4 0x00 0x03 0x10 0x13 0x8000 0x5600 0x5700
			0x00 0xA5 0x38 0x3B 0x0C 0x0F 0x6200 0x8000 0x7000
			0x00 0xA6 0x34 0x37 0x0C 0x0F 0x6700 0x8000 0x7100
			0x00 0xA7 0x30 0x33 0x0C 0x0F 0x6a00 0x8000 0x7200
			0x00 0xA8 0x2C 0x2F 0x0C 0x0F 0x6d00 0x8000 0x7300
			0x00 0xA9 0x28 0x2B 0x0C 0x0F 0x7100 0x8000 0x7400
			0x00 0xAA 0x24 0x27 0x0C 0x0F 0x7500 0x8000 0x7480
			0x00 0xAB 0x20 0x23 0x0C 0x0F 0x7900 0x8000 0x7500
			0x00 0xAC 0x1C 0x1F 0x0C 0x0F 0x7f00 0x8000 0x7600
			0x00 0xAD 0x18 0x1B 0x0C 0x0F 0x8000 0x7b00 0x7200
			0x00 0xAE 0x14 0x17 0x0C 0x0F 0x8000 0x7300 0x6d00
			0x00 0xAF 0x10 0x13 0x0C 0x0F 0x8000 0x6d00 0x6800
			0x00 0xB0 0x0C 0x0F 0x0C 0x0F 0x8000 0x6800 0x6400
			0x00 0xB1 0x08 0x0B 0x0C 0x0F 0x8000 0x6100 0x5d00
			0x00 0xB2 0x04 0x07 0x0C 0x0F 0x8000 0x5b00 0x5900
			0x00 0xB3 0x00 0x03 0x0C 0x0F 0x8000 0x5600 0x5480
			0x00 0xB4 0x38 0x3B 0x08 0x0B 0x6200 0x8000 0x6e00
			0x00 0xB5 0x34 0x37 0x08 0x0B 0x6600 0x8000 0x6e00
			0x00 0xB6 0x30 0x33 0x08 0x0B 0x6900 0x8000 0x6f00
			0x00 0xB7 0x2C 0x2F 0x08 0x0B 0x6d00 0x8000 0x7000
			0x00 0xB8 0x28 0x2B 0x08 0x0B 0x7100 0x8000 0x7200
			0x00 0xB9 0x24 0x27 0x08 0x0B 0x7500 0x8000 0x7200
			0x00 0xBA 0x20 0x23 0x08 0x0B 0x7a00 0x8000 0x7200
			0x00 0xBB 0x1C 0x1F 0x08 0x0B 0x7f00 0x8000 0x7300
			0x00 0xBC 0x18 0x1B 0x08 0x0B 0x8000 0x7b00 0x7000
			0x00 0xBD 0x14 0x17 0x08 0x0B 0x8000 0x7200 0x6a00
			0x00 0xBE 0x10 0x13 0x08 0x0B 0x8000 0x6c00 0x6500
			0x00 0xBF 0x0C 0x0F 0x08 0x0B 0x8000 0x6600 0x6000
			0x00 0xC0 0x08 0x0B 0x08 0x0B 0x8000 0x6000 0x5b00
			0x00 0xC1 0x04 0x07 0x08 0x0B 0x8000 0x5b00 0x5700
			0x00 0xC2 0x00 0x03 0x08 0x0B 0x8000 0x5500 0x5100
			0x00 0xC3 0x38 0x3B 0x04 0x07 0x6200 0x8000 0x6b00
			0x00 0xC4 0x34 0x37 0x04 0x07 0x6500 0x8000 0x6c00
			0x00 0xC5 0x30 0x33 0x04 0x07 0x6800 0x8000 0x6d80
			0x00 0xC6 0x2C 0x2F 0x04 0x07 0x6c00 0x8000 0x6e00
			0x00 0xC7 0x28 0x2B 0x04 0x07 0x7000 0x8000 0x6e00
			0x00 0xC8 0x24 0x27 0x04 0x07 0x7400 0x8000 0x6f00
			0x00 0xC9 0x20 0x23 0x04 0x07 0x7800 0x8000 0x7000
			0x00 0xCA 0x1C 0x1F 0x04 0x07 0x7e00 0x8000 0x7000
			0x00 0xCB 0x18 0x1B 0x04 0x07 0x8000 0x7a80 0x6b80
			0x00 0xCC 0x14 0x17 0x04 0x07 0x8000 0x7400 0x6780
			0x00 0xCD 0x10 0x13 0x04 0x07 0x8000 0x6e00 0x6380
			0x00 0xCE 0x0C 0x0F 0x04 0x07 0x8000 0x6700 0x5e00
			0x00 0xCF 0x08 0x0B 0x04 0x07 0x8000 0x6180 0x5980
			0x00 0xD0 0x04 0x07 0x04 0x07 0x8000 0x5b00 0x5500
			0x00 0xD1 0x00 0x03 0x04 0x07 0x8000 0x5500 0x5100
			0x00 0xD2 0x38 0x3B 0x00 0x03 0x6100 0x8000 0x6900
			0x00 0xD3 0x34 0x37 0x00 0x03 0x6400 0x8000 0x6a00
			0x00 0xD4 0x30 0x33 0x00 0x03 0x6800 0x8000 0x6b00
			0x00 0xD5 0x2C 0x2F 0x00 0x03 0x6c00 0x8000 0x6b80
			0x00 0xD6 0x28 0x2B 0x00 0x03 0x6f00 0x8000 0x6c00
			0x00 0xD7 0x24 0x27 0x00 0x03 0x7300 0x8000 0x6d00
			0x00 0xD8 0x20 0x23 0x00 0x03 0x7900 0x8000 0x6d00
			0x00 0xD9 0x1C 0x1F 0x00 0x03 0x7f00 0x8000 0x6e00
			0x00 0xDA 0x18 0x1B 0x00 0x03 0x8000 0x7b00 0x6a80
			0x00 0xDB 0x14 0x17 0x00 0x03 0x8000 0x7400 0x6580
			0x00 0xDC 0x10 0x13 0x00 0x03 0x8000 0x6d00 0x6180
			0x00 0xDD 0x0C 0x0F 0x00 0x03 0x8000 0x6900 0x5e00
			0x00 0xDE 0x08 0x0B 0x00 0x03 0x8000 0x6200 0x5800
			0x00 0xDF 0x04 0x07 0x00 0x03 0x8000 0x5a00 0x5200
			0x00 0xE0 0x00 0x03 0x00 0x03 0x8000 0x5400 0x4d00
			0xFF 0x00 0x00 0x3B 0x00 0x3B 0x8000 0x8000 0x8000>;

		somc,chenge-fps-command = [15 01 00 00 00 00 02 FF 24
				15 01 00 00 00 00 02 92 95
				15 01 00 00 00 00 02 FF 10
				39 01 00 00 00 00 03 44 03 00];
		somc,chenge-fps-default = <0x95>;
		somc,display-clock = <17330000>;
		somc,driver-ic-vbp = <8>;
		somc,driver-ic-vfp = <2>;
		somc,chenge-fps-cmds-num = <1>;
		somc,chenge-fps-payload-num = <1>;

		somc,chenge-wait-update = <1>;
		somc,chenge-wait-on = <40 60>;
		somc,chenge-wait-off = <80 90>;
		somc,chenge-wait-cmds-num = <0 2>;
		somc,fps-threshold = <47400>;
		somc,te-c-update = <1>;
		somc,te-c-mode-60fps = <0x03 0x00>;
		somc,te-c-mode-45fps = <0x04 0xFF>;
		somc,te-c-cmds-num = <3>;
		somc,te-c-payload-num = <1>;
	};

	dsi_novatek_jdi_1080_vid: somc,novatek_jdi_1080p_video_panel {
		qcom,mdss-dsi-panel-name = "jdi novatek 1080p video";
		qcom,mdss-dsi-panel-controller = <&mdss_dsi0>;
		qcom,mdss-dsi-panel-type = "dsi_video_mode";
		qcom,mdss-dsi-panel-destination = "display_1";
		qcom,mdss-dsi-panel-framerate = <60>;
		qcom,mdss-dsi-virtual-channel-id = <0>;
		qcom,mdss-dsi-stream = <0>;
		qcom,mdss-dsi-panel-width = <1080>;
		qcom,mdss-dsi-panel-height = <1920>;
		qcom,mdss-dsi-h-front-porch = <112>;
		qcom,mdss-dsi-h-back-porch = <76>;
		qcom,mdss-dsi-h-pulse-width = <4>;
		qcom,mdss-dsi-h-sync-skew = <0>;
		qcom,mdss-dsi-v-back-porch = <4>;
		qcom,mdss-dsi-v-front-porch = <8>;
		qcom,mdss-dsi-v-pulse-width = <4>;
		qcom,mdss-dsi-h-left-border = <0>;
		qcom,mdss-dsi-h-right-border = <0>;
		qcom,mdss-dsi-v-top-border = <0>;
		qcom,mdss-dsi-v-bottom-border = <0>;
		qcom,mdss-dsi-bpp = <24>;
		qcom,mdss-dsi-underflow-color = <0x0>;
		qcom,mdss-dsi-border-color = <0>;
		somc,mdss-dsi-init-command = [23 01 00 00 00 00 02 FF 10
				05 01 00 00 14 00 01 01
				15 01 00 00 00 00 02 BB 03
				15 01 00 00 00 00 02 35 00
				39 01 00 00 00 00 05 2A 00 00 04 37
				39 01 00 00 00 00 05 2B 00 00 07 7F
				39 01 00 00 00 00 04 3B 03 08 08];
		qcom,mdss-dsi-on-command = [05 01 00 00 64 00 01 11
				05 01 00 00 28 00 01 29];
		qcom,mdss-dsi-off-command = [05 01 00 00 14 00 01 28
				05 01 00 00 50 00 01 10];
		qcom,mdss-dsi-on-command-state = "dsi_lp_mode";
		qcom,mdss-dsi-off-command-state = "dsi_hs_mode";
		qcom,mdss-dsi-h-sync-pulse = <1>;
		qcom,mdss-dsi-traffic-mode = "non_burst_sync_event";
		qcom,mdss-dsi-bllp-eof-power-mode;
		qcom,mdss-dsi-bllp-power-mode;
		qcom,mdss-dsi-lane-0-state;
		qcom,mdss-dsi-lane-1-state;
		qcom,mdss-dsi-lane-2-state;
		qcom,mdss-dsi-lane-3-state;
		qcom,mdss-dsi-panel-timings = [E6 38 26 00 68 6C 2A 3A 2C 03 04 00];
		qcom,mdss-dsi-lp11-init;
		qcom,mdss-dsi-t-clk-post = <0x02>;
		qcom,mdss-dsi-t-clk-pre = <0x2B>;
		qcom,mdss-dsi-bl-min-level = <1>;
		qcom,mdss-dsi-bl-max-level = <4095>;
		qcom,mdss-brightness-max-level = <4095>;
		qcom,mdss-dsi-dma-trigger = "trigger_sw";
		qcom,mdss-dsi-mdp-trigger = "none";
		qcom,mdss-dsi-bl-pmic-control-type = "bl_ctrl_wled";
		qcom,mdss-dsi-pan-enable-dynamic-fps;
		qcom,mdss-dsi-pan-fps-update = "dfps_suspend_resume_mode";
		qcom,cont-splash-enabled;

		somc,driver-ic = <0>;
		somc,dric-gpio = <&msmgpio 26 0>;
		somc,touch-reset-gpio = <&msmgpio 85 0>;
		somc,mul-channel-scaling = <3>;
		somc,mdss-phy-size-mm = <64 114>;
		somc,mdss-dsi-lane-config = [00 c2 ef 00 00 00 00 01 ff
				00 c2 ef 00 00 00 00 01 ff
				00 c2 ef 00 00 00 00 01 ff
				00 c2 ef 00 00 00 00 01 ff
				00 02 45 00 00 00 00 01 97];
		somc,mdss-dsi-disp-on-in-hs = <1>;
		somc,mdss-dsi-wait-time-before-on-cmd = <150>;
		somc,lcd-id = <1>;
		somc,lcd-id-adc = <801000 917000>;
		somc,disp-en-on-post = <10>;
		somc,pw-on-rst-seq = <1 15>;
		somc,disp-en-off-post = <200>;
		somc,pw-off-rst-seq = <0 0>;
		somc,pw-down-period = <100>;

		somc,mdss-dsi-pre-uv-command = [23 01 00 00 00 00 02 B0 04];
		somc,mdss-dsi-uv-command = [06 01 00 00 00 00 01 DA
			06 01 00 00 00 00 01 DB];
		somc,mdss-dsi-uv-param-type = <4>;
		somc,mdss-dsi-pcc-table-size = <225>;
		somc,mdss-dsi-pcc-table = <
			0x00 0x01 0x38 0x3B 0x38 0x3B 0x5700 0x7000 0x8000
			0x00 0x02 0x34 0x37 0x38 0x3B 0x5900 0x6f00 0x8000
			0x00 0x03 0x30 0x33 0x38 0x3B 0x5c00 0x6e00 0x8000
			0x00 0x04 0x2C 0x2F 0x38 0x3B 0x5d80 0x6c80 0x8000
			0x00 0x05 0x28 0x2B 0x38 0x3B 0x6080 0x6c80 0x8000
			0x00 0x06 0x24 0x27 0x38 0x3B 0x6380 0x6c80 0x8000
			0x00 0x07 0x20 0x23 0x38 0x3B 0x6700 0x6c00 0x8000
			0x00 0x08 0x1C 0x1F 0x38 0x3B 0x6980 0x6b00 0x8000
			0x00 0x09 0x18 0x1B 0x38 0x3B 0x6d00 0x6a80 0x8000
			0x00 0x0A 0x14 0x17 0x38 0x3B 0x7180 0x6900 0x8000
			0x00 0x0B 0x10 0x13 0x38 0x3B 0x7800 0x6800 0x8000
			0x00 0x0C 0x0C 0x0F 0x38 0x3B 0x7d00 0x6700 0x8000
			0x00 0x0D 0x08 0x0B 0x38 0x3B 0x8000 0x6500 0x7d00
			0x00 0x0E 0x04 0x07 0x38 0x3B 0x8000 0x6000 0x7700
			0x00 0x0F 0x00 0x03 0x38 0x3B 0x8000 0x5900 0x7000
			0x00 0x10 0x38 0x3B 0x34 0x37 0x5900 0x7280 0x8000
			0x00 0x11 0x34 0x37 0x34 0x37 0x5b00 0x7100 0x8000
			0x00 0x12 0x30 0x33 0x34 0x37 0x5e00 0x7180 0x8000
			0x00 0x13 0x2C 0x2F 0x34 0x37 0x6080 0x7180 0x8000
			0x00 0x14 0x28 0x2B 0x34 0x37 0x6400 0x7000 0x8000
			0x00 0x15 0x24 0x27 0x34 0x37 0x6700 0x7000 0x8000
			0x00 0x16 0x20 0x23 0x34 0x37 0x6900 0x6f00 0x8000
			0x00 0x17 0x1C 0x1F 0x34 0x37 0x6c00 0x6e80 0x8000
			0x00 0x18 0x18 0x1B 0x34 0x37 0x7000 0x6d80 0x8000
			0x00 0x19 0x14 0x17 0x34 0x37 0x7580 0x6b80 0x8000
			0x00 0x1A 0x10 0x13 0x34 0x37 0x7b00 0x6a80 0x8000
			0x00 0x1B 0x0C 0x0F 0x34 0x37 0x8000 0x6a80 0x8000
			0x00 0x1C 0x08 0x0B 0x34 0x37 0x8000 0x6600 0x7c00
			0x00 0x1D 0x04 0x07 0x34 0x37 0x8000 0x6100 0x7400
			0x00 0x1E 0x00 0x03 0x34 0x37 0x8000 0x5b00 0x6e00
			0x00 0x1F 0x38 0x3B 0x30 0x33 0x5c80 0x7600 0x8000
			0x00 0x20 0x34 0x37 0x30 0x33 0x5e00 0x7500 0x8000
			0x00 0x21 0x30 0x33 0x30 0x33 0x6100 0x7480 0x8000
			0x00 0x22 0x2C 0x2F 0x30 0x33 0x6400 0x7400 0x8000
			0x00 0x23 0x28 0x2B 0x30 0x33 0x6500 0x7300 0x8000
			0x00 0x24 0x24 0x27 0x30 0x33 0x6880 0x7400 0x8000
			0x00 0x25 0x20 0x23 0x30 0x33 0x6b00 0x7200 0x8000
			0x00 0x26 0x1C 0x1F 0x30 0x33 0x6e00 0x6f00 0x8000
			0x00 0x27 0x18 0x1B 0x30 0x33 0x7300 0x7080 0x8000
			0x00 0x28 0x14 0x17 0x30 0x33 0x7700 0x6d80 0x8000
			0x00 0x29 0x10 0x13 0x30 0x33 0x7c00 0x6d80 0x8000
			0x00 0x2A 0x0C 0x0F 0x30 0x33 0x8000 0x6c00 0x7e00
			0x00 0x2B 0x08 0x0B 0x30 0x33 0x8000 0x6700 0x7a00
			0x00 0x2C 0x04 0x07 0x30 0x33 0x8000 0x6100 0x7200
			0x00 0x2D 0x00 0x03 0x30 0x33 0x8000 0x5b00 0x6c00
			0x00 0x2E 0x38 0x3B 0x2C 0x2F 0x5c00 0x7880 0x8000
			0x00 0x2F 0x34 0x37 0x2C 0x2F 0x5f00 0x7700 0x8000
			0x00 0x30 0x30 0x33 0x2C 0x2F 0x6100 0x7700 0x8000
			0x00 0x31 0x2C 0x2F 0x2C 0x2F 0x6500 0x7680 0x8000
			0x00 0x32 0x28 0x2B 0x2C 0x2F 0x6700 0x7600 0x8000
			0x00 0x33 0x24 0x27 0x2C 0x2F 0x6a00 0x7500 0x8000
			0x00 0x34 0x20 0x23 0x2C 0x2F 0x6e00 0x7500 0x8000
			0x00 0x35 0x1C 0x1F 0x2C 0x2F 0x7180 0x7400 0x8000
			0x00 0x36 0x18 0x1B 0x2C 0x2F 0x7580 0x7300 0x8000
			0x00 0x37 0x14 0x17 0x2C 0x2F 0x7b00 0x7080 0x8000
			0x00 0x38 0x10 0x13 0x2C 0x2F 0x8000 0x7080 0x7f00
			0x00 0x39 0x0C 0x0F 0x2C 0x2F 0x8000 0x6b00 0x7a00
			0x00 0x3A 0x08 0x0B 0x2C 0x2F 0x8000 0x6500 0x7400
			0x00 0x3B 0x04 0x07 0x2C 0x2F 0x8000 0x6000 0x6d00
			0x00 0x3C 0x00 0x03 0x2C 0x2F 0x8000 0x5a00 0x6800
			0x00 0x3D 0x38 0x3B 0x28 0x2B 0x6000 0x7c00 0x8000
			0x00 0x3E 0x34 0x37 0x28 0x2B 0x6200 0x7b00 0x8000
			0x00 0x3F 0x30 0x33 0x28 0x2B 0x6600 0x7b00 0x8000
			0x00 0x40 0x2C 0x2F 0x28 0x2B 0x6900 0x7c00 0x8000
			0x00 0x41 0x28 0x2B 0x28 0x2B 0x6b80 0x7900 0x8000
			0x00 0x42 0x24 0x27 0x28 0x2B 0x6e00 0x7900 0x8000
			0x00 0x43 0x20 0x23 0x28 0x2B 0x7100 0x7780 0x8000
			0x00 0x44 0x1C 0x1F 0x28 0x2B 0x7500 0x7700 0x8000
			0x00 0x45 0x18 0x1B 0x28 0x2B 0x7a00 0x7600 0x8000
			0x00 0x46 0x14 0x17 0x28 0x2B 0x8000 0x7500 0x8000
			0x00 0x47 0x10 0x13 0x28 0x2B 0x8000 0x7000 0x7c00
			0x00 0x48 0x0C 0x0F 0x28 0x2B 0x8000 0x6b00 0x7800
			0x00 0x49 0x08 0x0B 0x28 0x2B 0x8000 0x6600 0x7200
			0x00 0x4A 0x04 0x07 0x28 0x2B 0x8000 0x6000 0x6c00
			0x00 0x4B 0x00 0x03 0x28 0x2B 0x8000 0x5900 0x6500
			0x00 0x4C 0x38 0x3B 0x24 0x27 0x6200 0x8000 0x8000
			0x00 0x4D 0x34 0x37 0x24 0x27 0x6500 0x7f00 0x8000
			0x00 0x4E 0x30 0x33 0x24 0x27 0x6800 0x7f00 0x8000
			0x00 0x4F 0x2C 0x2F 0x24 0x27 0x6b00 0x7e00 0x8000
			0x00 0x50 0x28 0x2B 0x24 0x27 0x6e00 0x7c80 0x8000
			0x00 0x51 0x24 0x27 0x24 0x27 0x7200 0x7d00 0x8000
			0x00 0x52 0x20 0x23 0x24 0x27 0x7500 0x7a00 0x8000
			0x00 0x53 0x1C 0x1F 0x24 0x27 0x7900 0x7a00 0x8000
			0x00 0x54 0x18 0x1B 0x24 0x27 0x7e00 0x7a00 0x8000
			0x00 0x55 0x14 0x17 0x24 0x27 0x8000 0x7300 0x7c00
			0x00 0x56 0x10 0x13 0x24 0x27 0x8000 0x6e00 0x7800
			0x00 0x57 0x0C 0x0F 0x24 0x27 0x8000 0x6900 0x7300
			0x00 0x58 0x08 0x0B 0x24 0x27 0x8000 0x6400 0x6d00
			0x00 0x59 0x04 0x07 0x24 0x27 0x8000 0x5e00 0x6800
			0x00 0x5A 0x00 0x03 0x24 0x27 0x8000 0x5900 0x6300
			0x00 0x5B 0x38 0x3B 0x20 0x23 0x6200 0x8000 0x7d00
			0x00 0x5C 0x34 0x37 0x20 0x23 0x6600 0x8000 0x7e00
			0x00 0x5D 0x30 0x33 0x20 0x23 0x6a00 0x8000 0x7f00
			0x00 0x5E 0x2C 0x2F 0x20 0x23 0x6d00 0x8000 0x7f00
			0x00 0x5F 0x28 0x2B 0x20 0x23 0x7100 0x8000 0x8000
			0x00 0x60 0x24 0x27 0x20 0x23 0x7400 0x7f00 0x8000
			0x00 0x61 0x20 0x23 0x20 0x23 0x7700 0x7e80 0x8000
			0x00 0x62 0x1C 0x1F 0x20 0x23 0x7b00 0x7d00 0x8000
			0x00 0x63 0x18 0x1B 0x20 0x23 0x7f00 0x7c00 0x8000
			0x00 0x64 0x14 0x17 0x20 0x23 0x8000 0x7500 0x7b00
			0x00 0x65 0x10 0x13 0x20 0x23 0x8000 0x7000 0x7600
			0x00 0x66 0x0C 0x0F 0x20 0x23 0x8000 0x6a00 0x7100
			0x00 0x67 0x08 0x0B 0x20 0x23 0x8000 0x6400 0x6b00
			0x00 0x68 0x04 0x07 0x20 0x23 0x8000 0x5e00 0x6600
			0x00 0x69 0x00 0x03 0x20 0x23 0x8000 0x5800 0x6000
			0x00 0x6A 0x38 0x3B 0x1C 0x1F 0x6300 0x8000 0x7a00
			0x00 0x6B 0x34 0x37 0x1C 0x1F 0x6600 0x8000 0x7b00
			0x00 0x6C 0x30 0x33 0x1C 0x1F 0x6a00 0x8000 0x7c00
			0x00 0x6D 0x2C 0x2F 0x1C 0x1F 0x6e00 0x8000 0x7d00
			0x00 0x6E 0x28 0x2B 0x1C 0x1F 0x7200 0x8000 0x7e00
			0x00 0x6F 0x24 0x27 0x1C 0x1F 0x7600 0x8000 0x7e00
			0x00 0x70 0x20 0x23 0x1C 0x1F 0x7a00 0x8000 0x7f00
			0x00 0x71 0x18 0x1B 0x1C 0x1F 0x8000 0x7c00 0x7c00
			0x00 0x72 0x14 0x17 0x1C 0x1F 0x8000 0x7400 0x7780
			0x00 0x73 0x10 0x13 0x1C 0x1F 0x8000 0x6f00 0x7300
			0x00 0x74 0x0C 0x0F 0x1C 0x1F 0x8000 0x6900 0x6e00
			0x00 0x75 0x08 0x0B 0x1C 0x1F 0x8000 0x6300 0x6800
			0x00 0x76 0x04 0x07 0x1C 0x1F 0x8000 0x5d00 0x6280
			0x00 0x77 0x00 0x03 0x1C 0x1F 0x8000 0x5800 0x5d00
			0x00 0x78 0x38 0x3B 0x18 0x1B 0x6300 0x8000 0x7800
			0x00 0x79 0x34 0x37 0x18 0x1B 0x6700 0x8000 0x7900
			0x00 0x7A 0x30 0x33 0x18 0x1B 0x6a00 0x8000 0x7900
			0x00 0x7B 0x2C 0x2F 0x18 0x1B 0x6e00 0x8000 0x7b00
			0x00 0x7C 0x28 0x2B 0x18 0x1B 0x7180 0x8000 0x7c00
			0x00 0x7D 0x24 0x27 0x18 0x1B 0x7500 0x8000 0x7b00
			0x00 0x7E 0x20 0x23 0x18 0x1B 0x7a00 0x8000 0x7c80
			0x00 0x7F 0x1C 0x1F 0x18 0x1B 0x8000 0x8000 0x7e00
			0x00 0x80 0x18 0x1B 0x18 0x1B 0x8000 0x7a00 0x7900
			0x00 0x81 0x14 0x17 0x18 0x1B 0x8000 0x7400 0x7500
			0x00 0x82 0x10 0x13 0x18 0x1B 0x8000 0x6e00 0x6f00
			0x00 0x83 0x0C 0x0F 0x18 0x1B 0x8000 0x6900 0x6b00
			0x00 0x84 0x08 0x0B 0x18 0x1B 0x8000 0x6200 0x6500
			0x00 0x85 0x04 0x07 0x18 0x1B 0x8000 0x5d00 0x6000
			0x00 0x86 0x00 0x03 0x18 0x1B 0x8000 0x5700 0x5b00
			0x00 0x87 0x38 0x3B 0x14 0x17 0x6300 0x8000 0x7580
			0x00 0x88 0x34 0x37 0x14 0x17 0x6700 0x8000 0x7680
			0x00 0x89 0x30 0x33 0x14 0x17 0x6a00 0x8000 0x7780
			0x00 0x8A 0x2C 0x2F 0x14 0x17 0x6d00 0x8000 0x7800
			0x00 0x8B 0x28 0x2B 0x14 0x17 0x7100 0x8000 0x7800
			0x00 0x8C 0x24 0x27 0x14 0x17 0x7500 0x8000 0x7980
			0x00 0x8D 0x20 0x23 0x14 0x17 0x7a00 0x8000 0x7a00
			0x00 0x8E 0x1C 0x1F 0x14 0x17 0x7f00 0x8000 0x7a80
			0x00 0x8F 0x18 0x1B 0x14 0x17 0x8000 0x7b00 0x7700
			0x00 0x90 0x14 0x17 0x14 0x17 0x8000 0x7300 0x7100
			0x00 0x91 0x10 0x13 0x14 0x17 0x8000 0x6d00 0x6d00
			0x00 0x92 0x0C 0x0F 0x14 0x17 0x8000 0x6800 0x6900
			0x00 0x93 0x08 0x0B 0x14 0x17 0x8000 0x6200 0x6300
			0x00 0x94 0x04 0x07 0x14 0x17 0x8000 0x5c00 0x5d00
			0x00 0x95 0x00 0x03 0x14 0x17 0x8000 0x5600 0x5900
			0x00 0x96 0x38 0x3B 0x10 0x13 0x6300 0x8000 0x7300
			0x00 0x97 0x34 0x37 0x10 0x13 0x6600 0x8000 0x7400
			0x00 0x98 0x30 0x33 0x10 0x13 0x6a00 0x8000 0x7500
			0x00 0x99 0x2C 0x2F 0x10 0x13 0x6e00 0x8000 0x7600
			0x00 0x9A 0x28 0x2B 0x10 0x13 0x7100 0x8000 0x7600
			0x00 0x9B 0x24 0x27 0x10 0x13 0x7500 0x8000 0x7700
			0x00 0x9C 0x20 0x23 0x10 0x13 0x7980 0x8000 0x7800
			0x00 0x9D 0x1C 0x1F 0x10 0x13 0x7f00 0x8000 0x7800
			0x00 0x9E 0x18 0x1B 0x10 0x13 0x8000 0x7b00 0x7500
			0x00 0x9F 0x14 0x17 0x10 0x13 0x8000 0x7300 0x6f00
			0x00 0xA0 0x10 0x13 0x10 0x13 0x8000 0x6d00 0x6b00
			0x00 0xA1 0x0C 0x0F 0x10 0x13 0x8000 0x6800 0x6600
			0x00 0xA2 0x08 0x0B 0x10 0x13 0x8000 0x6200 0x6000
			0x00 0xA3 0x04 0x07 0x10 0x13 0x8000 0x5b00 0x5b00
			0x00 0xA4 0x00 0x03 0x10 0x13 0x8000 0x5600 0x5700
			0x00 0xA5 0x38 0x3B 0x0C 0x0F 0x6200 0x8000 0x7000
			0x00 0xA6 0x34 0x37 0x0C 0x0F 0x6700 0x8000 0x7100
			0x00 0xA7 0x30 0x33 0x0C 0x0F 0x6a00 0x8000 0x7200
			0x00 0xA8 0x2C 0x2F 0x0C 0x0F 0x6d00 0x8000 0x7300
			0x00 0xA9 0x28 0x2B 0x0C 0x0F 0x7100 0x8000 0x7400
			0x00 0xAA 0x24 0x27 0x0C 0x0F 0x7500 0x8000 0x7480
			0x00 0xAB 0x20 0x23 0x0C 0x0F 0x7900 0x8000 0x7500
			0x00 0xAC 0x1C 0x1F 0x0C 0x0F 0x7f00 0x8000 0x7600
			0x00 0xAD 0x18 0x1B 0x0C 0x0F 0x8000 0x7b00 0x7200
			0x00 0xAE 0x14 0x17 0x0C 0x0F 0x8000 0x7300 0x6d00
			0x00 0xAF 0x10 0x13 0x0C 0x0F 0x8000 0x6d00 0x6800
			0x00 0xB0 0x0C 0x0F 0x0C 0x0F 0x8000 0x6800 0x6400
			0x00 0xB1 0x08 0x0B 0x0C 0x0F 0x8000 0x6100 0x5d00
			0x00 0xB2 0x04 0x07 0x0C 0x0F 0x8000 0x5b00 0x5900
			0x00 0xB3 0x00 0x03 0x0C 0x0F 0x8000 0x5600 0x5480
			0x00 0xB4 0x38 0x3B 0x08 0x0B 0x6200 0x8000 0x6e00
			0x00 0xB5 0x34 0x37 0x08 0x0B 0x6600 0x8000 0x6e00
			0x00 0xB6 0x30 0x33 0x08 0x0B 0x6900 0x8000 0x6f00
			0x00 0xB7 0x2C 0x2F 0x08 0x0B 0x6d00 0x8000 0x7000
			0x00 0xB8 0x28 0x2B 0x08 0x0B 0x7100 0x8000 0x7200
			0x00 0xB9 0x24 0x27 0x08 0x0B 0x7500 0x8000 0x7200
			0x00 0xBA 0x20 0x23 0x08 0x0B 0x7a00 0x8000 0x7200
			0x00 0xBB 0x1C 0x1F 0x08 0x0B 0x7f00 0x8000 0x7300
			0x00 0xBC 0x18 0x1B 0x08 0x0B 0x8000 0x7b00 0x7000
			0x00 0xBD 0x14 0x17 0x08 0x0B 0x8000 0x7200 0x6a00
			0x00 0xBE 0x10 0x13 0x08 0x0B 0x8000 0x6c00 0x6500
			0x00 0xBF 0x0C 0x0F 0x08 0x0B 0x8000 0x6600 0x6000
			0x00 0xC0 0x08 0x0B 0x08 0x0B 0x8000 0x6000 0x5b00
			0x00 0xC1 0x04 0x07 0x08 0x0B 0x8000 0x5b00 0x5700
			0x00 0xC2 0x00 0x03 0x08 0x0B 0x8000 0x5500 0x5100
			0x00 0xC3 0x38 0x3B 0x04 0x07 0x6200 0x8000 0x6b00
			0x00 0xC4 0x34 0x37 0x04 0x07 0x6500 0x8000 0x6c00
			0x00 0xC5 0x30 0x33 0x04 0x07 0x6800 0x8000 0x6d80
			0x00 0xC6 0x2C 0x2F 0x04 0x07 0x6c00 0x8000 0x6e00
			0x00 0xC7 0x28 0x2B 0x04 0x07 0x7000 0x8000 0x6e00
			0x00 0xC8 0x24 0x27 0x04 0x07 0x7400 0x8000 0x6f00
			0x00 0xC9 0x20 0x23 0x04 0x07 0x7800 0x8000 0x7000
			0x00 0xCA 0x1C 0x1F 0x04 0x07 0x7e00 0x8000 0x7000
			0x00 0xCB 0x18 0x1B 0x04 0x07 0x8000 0x7a80 0x6b80
			0x00 0xCC 0x14 0x17 0x04 0x07 0x8000 0x7400 0x6780
			0x00 0xCD 0x10 0x13 0x04 0x07 0x8000 0x6e00 0x6380
			0x00 0xCE 0x0C 0x0F 0x04 0x07 0x8000 0x6700 0x5e00
			0x00 0xCF 0x08 0x0B 0x04 0x07 0x8000 0x6180 0x5980
			0x00 0xD0 0x04 0x07 0x04 0x07 0x8000 0x5b00 0x5500
			0x00 0xD1 0x00 0x03 0x04 0x07 0x8000 0x5500 0x5100
			0x00 0xD2 0x38 0x3B 0x00 0x03 0x6100 0x8000 0x6900
			0x00 0xD3 0x34 0x37 0x00 0x03 0x6400 0x8000 0x6a00
			0x00 0xD4 0x30 0x33 0x00 0x03 0x6800 0x8000 0x6b00
			0x00 0xD5 0x2C 0x2F 0x00 0x03 0x6c00 0x8000 0x6b80
			0x00 0xD6 0x28 0x2B 0x00 0x03 0x6f00 0x8000 0x6c00
			0x00 0xD7 0x24 0x27 0x00 0x03 0x7300 0x8000 0x6d00
			0x00 0xD8 0x20 0x23 0x00 0x03 0x7900 0x8000 0x6d00
			0x00 0xD9 0x1C 0x1F 0x00 0x03 0x7f00 0x8000 0x6e00
			0x00 0xDA 0x18 0x1B 0x00 0x03 0x8000 0x7b00 0x6a80
			0x00 0xDB 0x14 0x17 0x00 0x03 0x8000 0x7400 0x6580
			0x00 0xDC 0x10 0x13 0x00 0x03 0x8000 0x6d00 0x6180
			0x00 0xDD 0x0C 0x0F 0x00 0x03 0x8000 0x6900 0x5e00
			0x00 0xDE 0x08 0x0B 0x00 0x03 0x8000 0x6200 0x5800
			0x00 0xDF 0x04 0x07 0x00 0x03 0x8000 0x5a00 0x5200
			0x00 0xE0 0x00 0x03 0x00 0x03 0x8000 0x5400 0x4d00
			0xFF 0x00 0x00 0x3B 0x00 0x3B 0x8000 0x8000 0x8000>;
	};

	dsi_novatek_jdi_1080_cmd: somc,novatek_jdi_1080p_cmd_panel {
		qcom,mdss-dsi-panel-name = "jdi novatek 1080p cmd";
		qcom,mdss-dsi-panel-controller = <&mdss_dsi0>;
		qcom,mdss-dsi-panel-type = "dsi_cmd_mode";
		qcom,mdss-dsi-panel-destination = "display_1";
		qcom,mdss-dsi-panel-framerate = <60>;
		qcom,mdss-dsi-virtual-channel-id = <0>;
		qcom,mdss-dsi-stream = <0>;
		qcom,mdss-dsi-panel-width = <1080>;
		qcom,mdss-dsi-panel-height = <1920>;
		qcom,mdss-dsi-h-front-porch = <56>;
		qcom,mdss-dsi-h-back-porch = <8>;
		qcom,mdss-dsi-h-pulse-width = <8>;
		qcom,mdss-dsi-h-sync-skew = <0>;
		qcom,mdss-dsi-v-back-porch = <4>;
		qcom,mdss-dsi-v-front-porch = <237>;
		qcom,mdss-dsi-v-pulse-width = <2>;
		qcom,mdss-dsi-h-left-border = <0>;
		qcom,mdss-dsi-h-right-border = <0>;
		qcom,mdss-dsi-v-top-border = <0>;
		qcom,mdss-dsi-v-bottom-border = <0>;
		qcom,mdss-dsi-bpp = <24>;
		qcom,mdss-dsi-underflow-color = <0x0>;
		qcom,mdss-dsi-border-color = <0>;
		somc,mdss-dsi-init-command = [23 01 00 00 00 00 02 FF 10
				05 01 00 00 14 00 01 01
				23 01 00 00 00 00 02 FF 10
				23 01 00 00 00 00 02 FB 01
				15 01 00 00 00 00 02 BB 10
				15 01 00 00 00 00 02 35 00
				15 01 00 00 00 00 02 44 03
				23 01 00 00 00 00 02 FF 24
				23 01 00 00 00 00 02 92 95
				23 01 00 00 00 00 02 FB 01
				15 01 00 00 00 00 02 C4 20
				23 01 00 00 00 00 02 FF 10
				23 01 00 00 00 00 02 FB 01
				05 01 00 00 64 00 01 11];
		qcom,mdss-dsi-on-command = [05 01 00 00 00 00 01 29];
		qcom,mdss-dsi-off-command = [15 01 00 00 00 00 02 FF 10
				05 01 00 00 14 00 01 28
				05 01 00 00 50 00 01 10];
		qcom,mdss-dsi-on-command-state = "dsi_hs_mode";
		qcom,mdss-dsi-off-command-state = "dsi_hs_mode";
		qcom,mdss-dsi-h-sync-pulse = <1>;
		qcom,mdss-dsi-traffic-mode = "non_burst_sync_event";
		qcom,mdss-dsi-bllp-eof-power-mode;
		qcom,mdss-dsi-bllp-power-mode;
		qcom,mdss-dsi-lane-0-state;
		qcom,mdss-dsi-lane-1-state;
		qcom,mdss-dsi-lane-2-state;
		qcom,mdss-dsi-lane-3-state;
		qcom,mdss-dsi-te-pin-select = <1>;
		qcom,mdss-dsi-wr-mem-start = <0x2c>;
		qcom,mdss-dsi-wr-mem-continue = <0x3c>;
		qcom,mdss-dsi-te-dcs-command = <1>;
		qcom,mdss-dsi-te-check-enable;
		qcom,mdss-dsi-te-using-te-pin;
		qcom,mdss-dsi-panel-timings = [E6 38 26 00 68 6E 2A 3C 2C 03 04 00];
		qcom,mdss-dsi-lp11-init;
		qcom,mdss-dsi-t-clk-post = <0x21>;
		qcom,mdss-dsi-t-clk-pre = <0x2B>;
		qcom,mdss-dsi-bl-min-level = <1>;
		qcom,mdss-dsi-bl-max-level = <4095>;
		qcom,mdss-brightness-max-level = <4095>;
		qcom,mdss-dsi-dma-trigger = "trigger_sw";
		qcom,mdss-dsi-mdp-trigger = "none";
		qcom,mdss-dsi-bl-pmic-control-type = "bl_ctrl_wled";
		qcom,mdss-dsi-pan-enable-dynamic-fps;
		qcom,mdss-dsi-pan-fps-update = "dfps_suspend_resume_mode";
		qcom,cont-splash-enabled;

		somc,driver-ic = <0>;
		somc,dric-gpio = <&msmgpio 26 0>;
		somc,touch-reset-gpio = <&msmgpio 85 0>;
		somc,mul-channel-scaling = <3>;
		somc,mdss-phy-size-mm = <64 114>;
		somc,mdss-dsi-lane-config = [00 c2 ef 00 00 00 00 01 ff
				00 c2 ef 00 00 00 00 01 ff
				00 c2 ef 00 00 00 00 01 ff
				00 c2 ef 00 00 00 00 01 ff
				00 02 45 00 00 00 00 01 97];
		somc,mdss-dsi-disp-on-in-hs = <0>;
		somc,mdss-dsi-wait-time-before-on-cmd = <150>;
		somc,lcd-id = <1>;
		somc,lcd-id-adc = <565000 653000>;
		somc,disp-en-on-post = <20>;
		somc,pw-on-rst-seq = <1 15>;
		somc,pw-off-rst-seq = <0 0>;
		somc,pw-down-period = <100>;

		somc,mdss-dsi-pre-uv-command = [23 01 00 00 00 00 02 B0 04];
		somc,mdss-dsi-uv-command = [06 01 00 00 00 00 01 DA
			06 01 00 00 00 00 01 DB];
		somc,mdss-dsi-uv-param-type = <4>;
		somc,mdss-dsi-pcc-table-size = <225>;
		somc,mdss-dsi-pcc-table = <
			0x00 0x01 0x38 0x3B 0x38 0x3B 0x5700 0x7000 0x8000
			0x00 0x02 0x34 0x37 0x38 0x3B 0x5900 0x6f00 0x8000
			0x00 0x03 0x30 0x33 0x38 0x3B 0x5c00 0x6e00 0x8000
			0x00 0x04 0x2C 0x2F 0x38 0x3B 0x5d80 0x6c80 0x8000
			0x00 0x05 0x28 0x2B 0x38 0x3B 0x6080 0x6c80 0x8000
			0x00 0x06 0x24 0x27 0x38 0x3B 0x6380 0x6c80 0x8000
			0x00 0x07 0x20 0x23 0x38 0x3B 0x6700 0x6c00 0x8000
			0x00 0x08 0x1C 0x1F 0x38 0x3B 0x6980 0x6b00 0x8000
			0x00 0x09 0x18 0x1B 0x38 0x3B 0x6d00 0x6a80 0x8000
			0x00 0x0A 0x14 0x17 0x38 0x3B 0x7180 0x6900 0x8000
			0x00 0x0B 0x10 0x13 0x38 0x3B 0x7800 0x6800 0x8000
			0x00 0x0C 0x0C 0x0F 0x38 0x3B 0x7d00 0x6700 0x8000
			0x00 0x0D 0x08 0x0B 0x38 0x3B 0x8000 0x6500 0x7d00
			0x00 0x0E 0x04 0x07 0x38 0x3B 0x8000 0x6000 0x7700
			0x00 0x0F 0x00 0x03 0x38 0x3B 0x8000 0x5900 0x7000
			0x00 0x10 0x38 0x3B 0x34 0x37 0x5900 0x7280 0x8000
			0x00 0x11 0x34 0x37 0x34 0x37 0x5b00 0x7100 0x8000
			0x00 0x12 0x30 0x33 0x34 0x37 0x5e00 0x7180 0x8000
			0x00 0x13 0x2C 0x2F 0x34 0x37 0x6080 0x7180 0x8000
			0x00 0x14 0x28 0x2B 0x34 0x37 0x6400 0x7000 0x8000
			0x00 0x15 0x24 0x27 0x34 0x37 0x6700 0x7000 0x8000
			0x00 0x16 0x20 0x23 0x34 0x37 0x6900 0x6f00 0x8000
			0x00 0x17 0x1C 0x1F 0x34 0x37 0x6c00 0x6e80 0x8000
			0x00 0x18 0x18 0x1B 0x34 0x37 0x7000 0x6d80 0x8000
			0x00 0x19 0x14 0x17 0x34 0x37 0x7580 0x6b80 0x8000
			0x00 0x1A 0x10 0x13 0x34 0x37 0x7b00 0x6a80 0x8000
			0x00 0x1B 0x0C 0x0F 0x34 0x37 0x8000 0x6a80 0x8000
			0x00 0x1C 0x08 0x0B 0x34 0x37 0x8000 0x6600 0x7c00
			0x00 0x1D 0x04 0x07 0x34 0x37 0x8000 0x6100 0x7400
			0x00 0x1E 0x00 0x03 0x34 0x37 0x8000 0x5b00 0x6e00
			0x00 0x1F 0x38 0x3B 0x30 0x33 0x5c80 0x7600 0x8000
			0x00 0x20 0x34 0x37 0x30 0x33 0x5e00 0x7500 0x8000
			0x00 0x21 0x30 0x33 0x30 0x33 0x6100 0x7480 0x8000
			0x00 0x22 0x2C 0x2F 0x30 0x33 0x6400 0x7400 0x8000
			0x00 0x23 0x28 0x2B 0x30 0x33 0x6500 0x7300 0x8000
			0x00 0x24 0x24 0x27 0x30 0x33 0x6880 0x7400 0x8000
			0x00 0x25 0x20 0x23 0x30 0x33 0x6b00 0x7200 0x8000
			0x00 0x26 0x1C 0x1F 0x30 0x33 0x6e00 0x6f00 0x8000
			0x00 0x27 0x18 0x1B 0x30 0x33 0x7300 0x7080 0x8000
			0x00 0x28 0x14 0x17 0x30 0x33 0x7700 0x6d80 0x8000
			0x00 0x29 0x10 0x13 0x30 0x33 0x7c00 0x6d80 0x8000
			0x00 0x2A 0x0C 0x0F 0x30 0x33 0x8000 0x6c00 0x7e00
			0x00 0x2B 0x08 0x0B 0x30 0x33 0x8000 0x6700 0x7a00
			0x00 0x2C 0x04 0x07 0x30 0x33 0x8000 0x6100 0x7200
			0x00 0x2D 0x00 0x03 0x30 0x33 0x8000 0x5b00 0x6c00
			0x00 0x2E 0x38 0x3B 0x2C 0x2F 0x5c00 0x7880 0x8000
			0x00 0x2F 0x34 0x37 0x2C 0x2F 0x5f00 0x7700 0x8000
			0x00 0x30 0x30 0x33 0x2C 0x2F 0x6100 0x7700 0x8000
			0x00 0x31 0x2C 0x2F 0x2C 0x2F 0x6500 0x7680 0x8000
			0x00 0x32 0x28 0x2B 0x2C 0x2F 0x6700 0x7600 0x8000
			0x00 0x33 0x24 0x27 0x2C 0x2F 0x6a00 0x7500 0x8000
			0x00 0x34 0x20 0x23 0x2C 0x2F 0x6e00 0x7500 0x8000
			0x00 0x35 0x1C 0x1F 0x2C 0x2F 0x7180 0x7400 0x8000
			0x00 0x36 0x18 0x1B 0x2C 0x2F 0x7580 0x7300 0x8000
			0x00 0x37 0x14 0x17 0x2C 0x2F 0x7b00 0x7080 0x8000
			0x00 0x38 0x10 0x13 0x2C 0x2F 0x8000 0x7080 0x7f00
			0x00 0x39 0x0C 0x0F 0x2C 0x2F 0x8000 0x6b00 0x7a00
			0x00 0x3A 0x08 0x0B 0x2C 0x2F 0x8000 0x6500 0x7400
			0x00 0x3B 0x04 0x07 0x2C 0x2F 0x8000 0x6000 0x6d00
			0x00 0x3C 0x00 0x03 0x2C 0x2F 0x8000 0x5a00 0x6800
			0x00 0x3D 0x38 0x3B 0x28 0x2B 0x6000 0x7c00 0x8000
			0x00 0x3E 0x34 0x37 0x28 0x2B 0x6200 0x7b00 0x8000
			0x00 0x3F 0x30 0x33 0x28 0x2B 0x6600 0x7b00 0x8000
			0x00 0x40 0x2C 0x2F 0x28 0x2B 0x6900 0x7c00 0x8000
			0x00 0x41 0x28 0x2B 0x28 0x2B 0x6b80 0x7900 0x8000
			0x00 0x42 0x24 0x27 0x28 0x2B 0x6e00 0x7900 0x8000
			0x00 0x43 0x20 0x23 0x28 0x2B 0x7100 0x7780 0x8000
			0x00 0x44 0x1C 0x1F 0x28 0x2B 0x7500 0x7700 0x8000
			0x00 0x45 0x18 0x1B 0x28 0x2B 0x7a00 0x7600 0x8000
			0x00 0x46 0x14 0x17 0x28 0x2B 0x8000 0x7500 0x8000
			0x00 0x47 0x10 0x13 0x28 0x2B 0x8000 0x7000 0x7c00
			0x00 0x48 0x0C 0x0F 0x28 0x2B 0x8000 0x6b00 0x7800
			0x00 0x49 0x08 0x0B 0x28 0x2B 0x8000 0x6600 0x7200
			0x00 0x4A 0x04 0x07 0x28 0x2B 0x8000 0x6000 0x6c00
			0x00 0x4B 0x00 0x03 0x28 0x2B 0x8000 0x5900 0x6500
			0x00 0x4C 0x38 0x3B 0x24 0x27 0x6200 0x8000 0x8000
			0x00 0x4D 0x34 0x37 0x24 0x27 0x6500 0x7f00 0x8000
			0x00 0x4E 0x30 0x33 0x24 0x27 0x6800 0x7f00 0x8000
			0x00 0x4F 0x2C 0x2F 0x24 0x27 0x6b00 0x7e00 0x8000
			0x00 0x50 0x28 0x2B 0x24 0x27 0x6e00 0x7c80 0x8000
			0x00 0x51 0x24 0x27 0x24 0x27 0x7200 0x7d00 0x8000
			0x00 0x52 0x20 0x23 0x24 0x27 0x7500 0x7a00 0x8000
			0x00 0x53 0x1C 0x1F 0x24 0x27 0x7900 0x7a00 0x8000
			0x00 0x54 0x18 0x1B 0x24 0x27 0x7e00 0x7a00 0x8000
			0x00 0x55 0x14 0x17 0x24 0x27 0x8000 0x7300 0x7c00
			0x00 0x56 0x10 0x13 0x24 0x27 0x8000 0x6e00 0x7800
			0x00 0x57 0x0C 0x0F 0x24 0x27 0x8000 0x6900 0x7300
			0x00 0x58 0x08 0x0B 0x24 0x27 0x8000 0x6400 0x6d00
			0x00 0x59 0x04 0x07 0x24 0x27 0x8000 0x5e00 0x6800
			0x00 0x5A 0x00 0x03 0x24 0x27 0x8000 0x5900 0x6300
			0x00 0x5B 0x38 0x3B 0x20 0x23 0x6200 0x8000 0x7d00
			0x00 0x5C 0x34 0x37 0x20 0x23 0x6600 0x8000 0x7e00
			0x00 0x5D 0x30 0x33 0x20 0x23 0x6a00 0x8000 0x7f00
			0x00 0x5E 0x2C 0x2F 0x20 0x23 0x6d00 0x8000 0x7f00
			0x00 0x5F 0x28 0x2B 0x20 0x23 0x7100 0x8000 0x8000
			0x00 0x60 0x24 0x27 0x20 0x23 0x7400 0x7f00 0x8000
			0x00 0x61 0x20 0x23 0x20 0x23 0x7700 0x7e80 0x8000
			0x00 0x62 0x1C 0x1F 0x20 0x23 0x7b00 0x7d00 0x8000
			0x00 0x63 0x18 0x1B 0x20 0x23 0x7f00 0x7c00 0x8000
			0x00 0x64 0x14 0x17 0x20 0x23 0x8000 0x7500 0x7b00
			0x00 0x65 0x10 0x13 0x20 0x23 0x8000 0x7000 0x7600
			0x00 0x66 0x0C 0x0F 0x20 0x23 0x8000 0x6a00 0x7100
			0x00 0x67 0x08 0x0B 0x20 0x23 0x8000 0x6400 0x6b00
			0x00 0x68 0x04 0x07 0x20 0x23 0x8000 0x5e00 0x6600
			0x00 0x69 0x00 0x03 0x20 0x23 0x8000 0x5800 0x6000
			0x00 0x6A 0x38 0x3B 0x1C 0x1F 0x6300 0x8000 0x7a00
			0x00 0x6B 0x34 0x37 0x1C 0x1F 0x6600 0x8000 0x7b00
			0x00 0x6C 0x30 0x33 0x1C 0x1F 0x6a00 0x8000 0x7c00
			0x00 0x6D 0x2C 0x2F 0x1C 0x1F 0x6e00 0x8000 0x7d00
			0x00 0x6E 0x28 0x2B 0x1C 0x1F 0x7200 0x8000 0x7e00
			0x00 0x6F 0x24 0x27 0x1C 0x1F 0x7600 0x8000 0x7e00
			0x00 0x70 0x20 0x23 0x1C 0x1F 0x7a00 0x8000 0x7f00
			0x00 0x71 0x18 0x1B 0x1C 0x1F 0x8000 0x7c00 0x7c00
			0x00 0x72 0x14 0x17 0x1C 0x1F 0x8000 0x7400 0x7780
			0x00 0x73 0x10 0x13 0x1C 0x1F 0x8000 0x6f00 0x7300
			0x00 0x74 0x0C 0x0F 0x1C 0x1F 0x8000 0x6900 0x6e00
			0x00 0x75 0x08 0x0B 0x1C 0x1F 0x8000 0x6300 0x6800
			0x00 0x76 0x04 0x07 0x1C 0x1F 0x8000 0x5d00 0x6280
			0x00 0x77 0x00 0x03 0x1C 0x1F 0x8000 0x5800 0x5d00
			0x00 0x78 0x38 0x3B 0x18 0x1B 0x6300 0x8000 0x7800
			0x00 0x79 0x34 0x37 0x18 0x1B 0x6700 0x8000 0x7900
			0x00 0x7A 0x30 0x33 0x18 0x1B 0x6a00 0x8000 0x7900
			0x00 0x7B 0x2C 0x2F 0x18 0x1B 0x6e00 0x8000 0x7b00
			0x00 0x7C 0x28 0x2B 0x18 0x1B 0x7180 0x8000 0x7c00
			0x00 0x7D 0x24 0x27 0x18 0x1B 0x7500 0x8000 0x7b00
			0x00 0x7E 0x20 0x23 0x18 0x1B 0x7a00 0x8000 0x7c80
			0x00 0x7F 0x1C 0x1F 0x18 0x1B 0x8000 0x8000 0x7e00
			0x00 0x80 0x18 0x1B 0x18 0x1B 0x8000 0x7a00 0x7900
			0x00 0x81 0x14 0x17 0x18 0x1B 0x8000 0x7400 0x7500
			0x00 0x82 0x10 0x13 0x18 0x1B 0x8000 0x6e00 0x6f00
			0x00 0x83 0x0C 0x0F 0x18 0x1B 0x8000 0x6900 0x6b00
			0x00 0x84 0x08 0x0B 0x18 0x1B 0x8000 0x6200 0x6500
			0x00 0x85 0x04 0x07 0x18 0x1B 0x8000 0x5d00 0x6000
			0x00 0x86 0x00 0x03 0x18 0x1B 0x8000 0x5700 0x5b00
			0x00 0x87 0x38 0x3B 0x14 0x17 0x6300 0x8000 0x7580
			0x00 0x88 0x34 0x37 0x14 0x17 0x6700 0x8000 0x7680
			0x00 0x89 0x30 0x33 0x14 0x17 0x6a00 0x8000 0x7780
			0x00 0x8A 0x2C 0x2F 0x14 0x17 0x6d00 0x8000 0x7800
			0x00 0x8B 0x28 0x2B 0x14 0x17 0x7100 0x8000 0x7800
			0x00 0x8C 0x24 0x27 0x14 0x17 0x7500 0x8000 0x7980
			0x00 0x8D 0x20 0x23 0x14 0x17 0x7a00 0x8000 0x7a00
			0x00 0x8E 0x1C 0x1F 0x14 0x17 0x7f00 0x8000 0x7a80
			0x00 0x8F 0x18 0x1B 0x14 0x17 0x8000 0x7b00 0x7700
			0x00 0x90 0x14 0x17 0x14 0x17 0x8000 0x7300 0x7100
			0x00 0x91 0x10 0x13 0x14 0x17 0x8000 0x6d00 0x6d00
			0x00 0x92 0x0C 0x0F 0x14 0x17 0x8000 0x6800 0x6900
			0x00 0x93 0x08 0x0B 0x14 0x17 0x8000 0x6200 0x6300
			0x00 0x94 0x04 0x07 0x14 0x17 0x8000 0x5c00 0x5d00
			0x00 0x95 0x00 0x03 0x14 0x17 0x8000 0x5600 0x5900
			0x00 0x96 0x38 0x3B 0x10 0x13 0x6300 0x8000 0x7300
			0x00 0x97 0x34 0x37 0x10 0x13 0x6600 0x8000 0x7400
			0x00 0x98 0x30 0x33 0x10 0x13 0x6a00 0x8000 0x7500
			0x00 0x99 0x2C 0x2F 0x10 0x13 0x6e00 0x8000 0x7600
			0x00 0x9A 0x28 0x2B 0x10 0x13 0x7100 0x8000 0x7600
			0x00 0x9B 0x24 0x27 0x10 0x13 0x7500 0x8000 0x7700
			0x00 0x9C 0x20 0x23 0x10 0x13 0x7980 0x8000 0x7800
			0x00 0x9D 0x1C 0x1F 0x10 0x13 0x7f00 0x8000 0x7800
			0x00 0x9E 0x18 0x1B 0x10 0x13 0x8000 0x7b00 0x7500
			0x00 0x9F 0x14 0x17 0x10 0x13 0x8000 0x7300 0x6f00
			0x00 0xA0 0x10 0x13 0x10 0x13 0x8000 0x6d00 0x6b00
			0x00 0xA1 0x0C 0x0F 0x10 0x13 0x8000 0x6800 0x6600
			0x00 0xA2 0x08 0x0B 0x10 0x13 0x8000 0x6200 0x6000
			0x00 0xA3 0x04 0x07 0x10 0x13 0x8000 0x5b00 0x5b00
			0x00 0xA4 0x00 0x03 0x10 0x13 0x8000 0x5600 0x5700
			0x00 0xA5 0x38 0x3B 0x0C 0x0F 0x6200 0x8000 0x7000
			0x00 0xA6 0x34 0x37 0x0C 0x0F 0x6700 0x8000 0x7100
			0x00 0xA7 0x30 0x33 0x0C 0x0F 0x6a00 0x8000 0x7200
			0x00 0xA8 0x2C 0x2F 0x0C 0x0F 0x6d00 0x8000 0x7300
			0x00 0xA9 0x28 0x2B 0x0C 0x0F 0x7100 0x8000 0x7400
			0x00 0xAA 0x24 0x27 0x0C 0x0F 0x7500 0x8000 0x7480
			0x00 0xAB 0x20 0x23 0x0C 0x0F 0x7900 0x8000 0x7500
			0x00 0xAC 0x1C 0x1F 0x0C 0x0F 0x7f00 0x8000 0x7600
			0x00 0xAD 0x18 0x1B 0x0C 0x0F 0x8000 0x7b00 0x7200
			0x00 0xAE 0x14 0x17 0x0C 0x0F 0x8000 0x7300 0x6d00
			0x00 0xAF 0x10 0x13 0x0C 0x0F 0x8000 0x6d00 0x6800
			0x00 0xB0 0x0C 0x0F 0x0C 0x0F 0x8000 0x6800 0x6400
			0x00 0xB1 0x08 0x0B 0x0C 0x0F 0x8000 0x6100 0x5d00
			0x00 0xB2 0x04 0x07 0x0C 0x0F 0x8000 0x5b00 0x5900
			0x00 0xB3 0x00 0x03 0x0C 0x0F 0x8000 0x5600 0x5480
			0x00 0xB4 0x38 0x3B 0x08 0x0B 0x6200 0x8000 0x6e00
			0x00 0xB5 0x34 0x37 0x08 0x0B 0x6600 0x8000 0x6e00
			0x00 0xB6 0x30 0x33 0x08 0x0B 0x6900 0x8000 0x6f00
			0x00 0xB7 0x2C 0x2F 0x08 0x0B 0x6d00 0x8000 0x7000
			0x00 0xB8 0x28 0x2B 0x08 0x0B 0x7100 0x8000 0x7200
			0x00 0xB9 0x24 0x27 0x08 0x0B 0x7500 0x8000 0x7200
			0x00 0xBA 0x20 0x23 0x08 0x0B 0x7a00 0x8000 0x7200
			0x00 0xBB 0x1C 0x1F 0x08 0x0B 0x7f00 0x8000 0x7300
			0x00 0xBC 0x18 0x1B 0x08 0x0B 0x8000 0x7b00 0x7000
			0x00 0xBD 0x14 0x17 0x08 0x0B 0x8000 0x7200 0x6a00
			0x00 0xBE 0x10 0x13 0x08 0x0B 0x8000 0x6c00 0x6500
			0x00 0xBF 0x0C 0x0F 0x08 0x0B 0x8000 0x6600 0x6000
			0x00 0xC0 0x08 0x0B 0x08 0x0B 0x8000 0x6000 0x5b00
			0x00 0xC1 0x04 0x07 0x08 0x0B 0x8000 0x5b00 0x5700
			0x00 0xC2 0x00 0x03 0x08 0x0B 0x8000 0x5500 0x5100
			0x00 0xC3 0x38 0x3B 0x04 0x07 0x6200 0x8000 0x6b00
			0x00 0xC4 0x34 0x37 0x04 0x07 0x6500 0x8000 0x6c00
			0x00 0xC5 0x30 0x33 0x04 0x07 0x6800 0x8000 0x6d80
			0x00 0xC6 0x2C 0x2F 0x04 0x07 0x6c00 0x8000 0x6e00
			0x00 0xC7 0x28 0x2B 0x04 0x07 0x7000 0x8000 0x6e00
			0x00 0xC8 0x24 0x27 0x04 0x07 0x7400 0x8000 0x6f00
			0x00 0xC9 0x20 0x23 0x04 0x07 0x7800 0x8000 0x7000
			0x00 0xCA 0x1C 0x1F 0x04 0x07 0x7e00 0x8000 0x7000
			0x00 0xCB 0x18 0x1B 0x04 0x07 0x8000 0x7a80 0x6b80
			0x00 0xCC 0x14 0x17 0x04 0x07 0x8000 0x7400 0x6780
			0x00 0xCD 0x10 0x13 0x04 0x07 0x8000 0x6e00 0x6380
			0x00 0xCE 0x0C 0x0F 0x04 0x07 0x8000 0x6700 0x5e00
			0x00 0xCF 0x08 0x0B 0x04 0x07 0x8000 0x6180 0x5980
			0x00 0xD0 0x04 0x07 0x04 0x07 0x8000 0x5b00 0x5500
			0x00 0xD1 0x00 0x03 0x04 0x07 0x8000 0x5500 0x5100
			0x00 0xD2 0x38 0x3B 0x00 0x03 0x6100 0x8000 0x6900
			0x00 0xD3 0x34 0x37 0x00 0x03 0x6400 0x8000 0x6a00
			0x00 0xD4 0x30 0x33 0x00 0x03 0x6800 0x8000 0x6b00
			0x00 0xD5 0x2C 0x2F 0x00 0x03 0x6c00 0x8000 0x6b80
			0x00 0xD6 0x28 0x2B 0x00 0x03 0x6f00 0x8000 0x6c00
			0x00 0xD7 0x24 0x27 0x00 0x03 0x7300 0x8000 0x6d00
			0x00 0xD8 0x20 0x23 0x00 0x03 0x7900 0x8000 0x6d00
			0x00 0xD9 0x1C 0x1F 0x00 0x03 0x7f00 0x8000 0x6e00
			0x00 0xDA 0x18 0x1B 0x00 0x03 0x8000 0x7b00 0x6a80
			0x00 0xDB 0x14 0x17 0x00 0x03 0x8000 0x7400 0x6580
			0x00 0xDC 0x10 0x13 0x00 0x03 0x8000 0x6d00 0x6180
			0x00 0xDD 0x0C 0x0F 0x00 0x03 0x8000 0x6900 0x5e00
			0x00 0xDE 0x08 0x0B 0x00 0x03 0x8000 0x6200 0x5800
			0x00 0xDF 0x04 0x07 0x00 0x03 0x8000 0x5a00 0x5200
			0x00 0xE0 0x00 0x03 0x00 0x03 0x8000 0x5400 0x4d00
			0xFF 0x00 0x00 0x3B 0x00 0x3B 0x8000 0x8000 0x8000>;

		somc,chenge-fps-command = [15 01 00 00 00 00 02 FF 24
				15 01 00 00 00 00 02 92 95
				15 01 00 00 00 00 02 FF 10
				15 01 00 00 00 00 02 44 03];
		somc,chenge-fps-default = <0x95>;
		somc,display-clock = <17330000>;
		somc,driver-ic-vbp = <8>;
		somc,driver-ic-vfp = <8>;
		somc,chenge-fps-cmds-num = <1>;
		somc,chenge-fps-payload-num = <1>;

		somc,chenge-wait-update = <0>;
		somc,chenge-wait-on = <0 0>;
		somc,chenge-wait-off = <0 0>;
		somc,chenge-wait-cmds-num = <0 0>;
		somc,fps-threshold = <47400>;
		somc,te-c-update = <1>;
		somc,te-c-mode-60fps = <0x03 0x00>;
		somc,te-c-mode-45fps = <0x05 0x00>;
		somc,te-c-cmds-num = <3>;
		somc,te-c-payload-num = <1>;
	};

	dsi_novatek_auo_1080_cmd: somc,novatek_auo_1080p_cmd_panel {
		qcom,mdss-dsi-panel-name = "auo novatek 1080p cmd";
		qcom,mdss-dsi-panel-controller = <&mdss_dsi0>;
		qcom,mdss-dsi-panel-type = "dsi_cmd_mode";
		qcom,mdss-dsi-panel-destination = "display_1";
		qcom,mdss-dsi-panel-framerate = <60>;
		qcom,mdss-dsi-virtual-channel-id = <0>;
		qcom,mdss-dsi-stream = <0>;
		qcom,mdss-dsi-panel-width = <1080>;
		qcom,mdss-dsi-panel-height = <1920>;
		qcom,mdss-dsi-h-front-porch = <56>;
		qcom,mdss-dsi-h-back-porch = <8>;
		qcom,mdss-dsi-h-pulse-width = <8>;
		qcom,mdss-dsi-h-sync-skew = <0>;
		qcom,mdss-dsi-v-back-porch = <4>;
		qcom,mdss-dsi-v-front-porch = <237>;
		qcom,mdss-dsi-v-pulse-width = <2>;
		qcom,mdss-dsi-h-left-border = <0>;
		qcom,mdss-dsi-h-right-border = <0>;
		qcom,mdss-dsi-v-top-border = <0>;
		qcom,mdss-dsi-v-bottom-border = <0>;
		qcom,mdss-dsi-bpp = <24>;
		qcom,mdss-dsi-underflow-color = <0x0>;
		qcom,mdss-dsi-border-color = <0>;
		somc,mdss-dsi-init-command = [15 01 00 00 00 00 02 FF 24
				15 01 00 00 00 00 02 FB 01
				15 01 00 00 00 00 02 C6 00
				15 01 00 00 00 00 02 C5 32
				15 01 00 00 00 00 02 92 92
				15 01 00 00 00 00 02 FF 10
				15 01 00 00 00 00 02 35 00
				39 01 00 00 00 00 03 44 03 00
				39 01 00 00 00 00 04 3B 03 30 06
				15 01 00 00 01 00 02 BB 10
				05 01 00 00 1E 00 01 11];
		qcom,mdss-dsi-on-command = [05 01 00 00 28 00 01 29];
		qcom,mdss-dsi-off-command = [15 01 00 00 00 00 02 FF 10
				05 01 00 00 00 00 01 28
				05 01 00 00 64 00 01 10];
		qcom,mdss-dsi-on-command-state = "dsi_hs_mode";
		qcom,mdss-dsi-off-command-state = "dsi_hs_mode";

		qcom,mdss-dsi-h-sync-pulse = <1>;
		qcom,mdss-dsi-traffic-mode = "non_burst_sync_event";
		qcom,mdss-dsi-bllp-eof-power-mode;
		qcom,mdss-dsi-bllp-power-mode;
		qcom,mdss-dsi-lane-0-state;
		qcom,mdss-dsi-lane-1-state;
		qcom,mdss-dsi-lane-2-state;
		qcom,mdss-dsi-lane-3-state;
		qcom,mdss-dsi-te-pin-select = <1>;
		qcom,mdss-dsi-wr-mem-start = <0x2c>;
		qcom,mdss-dsi-wr-mem-continue = <0x3c>;
		qcom,mdss-dsi-te-dcs-command = <1>;
		qcom,mdss-dsi-te-check-enable;
		qcom,mdss-dsi-te-using-te-pin;
		qcom,mdss-dsi-panel-timings = [E6 38 26 00 68 6E 2A 3C 2C 03 04 00];
		qcom,mdss-dsi-lp11-init;
		qcom,mdss-dsi-t-clk-post = <0x21>;
		qcom,mdss-dsi-t-clk-pre = <0x2B>;
		qcom,mdss-dsi-bl-min-level = <1>;
		qcom,mdss-dsi-bl-max-level = <4095>;
		qcom,mdss-brightness-max-level = <4095>;
		qcom,mdss-dsi-dma-trigger = "trigger_sw";
		qcom,mdss-dsi-mdp-trigger = "none";
		qcom,mdss-dsi-bl-pmic-control-type = "bl_ctrl_wled";
		qcom,mdss-dsi-pan-enable-dynamic-fps;
		qcom,mdss-dsi-pan-fps-update = "dfps_suspend_resume_mode";
		qcom,cont-splash-enabled;

		somc,driver-ic = <0>;
		somc,dric-gpio = <&msmgpio 26 0>;
		somc,touch-reset-gpio = <&msmgpio 85 0>;
		somc,mul-channel-scaling = <3>;
		somc,mdss-phy-size-mm = <64 114>;
		somc,mdss-dsi-lane-config = [00 c2 ef 00 00 00 00 01 ff
				00 c2 ef 00 00 00 00 01 ff
				00 c2 ef 00 00 00 00 01 ff
				00 c2 ef 00 00 00 00 01 ff
				00 02 45 00 00 00 00 01 97];
		somc,mdss-dsi-disp-on-in-hs = <0>;
		somc,mdss-dsi-wait-time-before-on-cmd = <100>;
		somc,lcd-id = <1>;
		somc,lcd-id-adc = <1236000 1395000>;
		somc,disp-en-on-post = <20>;
		somc,pw-on-rst-seq = <1 10>;
		somc,disp-en-off-post = <70>;
		somc,pw-off-rst-seq = <0 0>;
		somc,pw-down-period = <100>;

		somc,mdss-dsi-pre-uv-command = [23 01 00 00 00 00 02 B0 04];
		somc,mdss-dsi-uv-command = [06 01 00 00 00 00 01 DA
			06 01 00 00 00 00 01 DB];
		somc,mdss-dsi-uv-param-type = <4>;
		somc,mdss-dsi-pcc-table-size = <225>;
		somc,mdss-dsi-pcc-table = <
			0x00 0x01 0x38 0x3B 0x38 0x3B 0x5700 0x7000 0x8000
			0x00 0x02 0x34 0x37 0x38 0x3B 0x5900 0x6f00 0x8000
			0x00 0x03 0x30 0x33 0x38 0x3B 0x5c00 0x6e00 0x8000
			0x00 0x04 0x2C 0x2F 0x38 0x3B 0x5d80 0x6c80 0x8000
			0x00 0x05 0x28 0x2B 0x38 0x3B 0x6080 0x6c80 0x8000
			0x00 0x06 0x24 0x27 0x38 0x3B 0x6380 0x6c80 0x8000
			0x00 0x07 0x20 0x23 0x38 0x3B 0x6700 0x6c00 0x8000
			0x00 0x08 0x1C 0x1F 0x38 0x3B 0x6980 0x6b00 0x8000
			0x00 0x09 0x18 0x1B 0x38 0x3B 0x6d00 0x6a80 0x8000
			0x00 0x0A 0x14 0x17 0x38 0x3B 0x7180 0x6900 0x8000
			0x00 0x0B 0x10 0x13 0x38 0x3B 0x7800 0x6800 0x8000
			0x00 0x0C 0x0C 0x0F 0x38 0x3B 0x7d00 0x6700 0x8000
			0x00 0x0D 0x08 0x0B 0x38 0x3B 0x8000 0x6500 0x7d00
			0x00 0x0E 0x04 0x07 0x38 0x3B 0x8000 0x6000 0x7700
			0x00 0x0F 0x00 0x03 0x38 0x3B 0x8000 0x5900 0x7000
			0x00 0x10 0x38 0x3B 0x34 0x37 0x5900 0x7280 0x8000
			0x00 0x11 0x34 0x37 0x34 0x37 0x5b00 0x7100 0x8000
			0x00 0x12 0x30 0x33 0x34 0x37 0x5e00 0x7180 0x8000
			0x00 0x13 0x2C 0x2F 0x34 0x37 0x6080 0x7180 0x8000
			0x00 0x14 0x28 0x2B 0x34 0x37 0x6400 0x7000 0x8000
			0x00 0x15 0x24 0x27 0x34 0x37 0x6700 0x7000 0x8000
			0x00 0x16 0x20 0x23 0x34 0x37 0x6900 0x6f00 0x8000
			0x00 0x17 0x1C 0x1F 0x34 0x37 0x6c00 0x6e80 0x8000
			0x00 0x18 0x18 0x1B 0x34 0x37 0x7000 0x6d80 0x8000
			0x00 0x19 0x14 0x17 0x34 0x37 0x7580 0x6b80 0x8000
			0x00 0x1A 0x10 0x13 0x34 0x37 0x7b00 0x6a80 0x8000
			0x00 0x1B 0x0C 0x0F 0x34 0x37 0x8000 0x6a80 0x8000
			0x00 0x1C 0x08 0x0B 0x34 0x37 0x8000 0x6600 0x7c00
			0x00 0x1D 0x04 0x07 0x34 0x37 0x8000 0x6100 0x7400
			0x00 0x1E 0x00 0x03 0x34 0x37 0x8000 0x5b00 0x6e00
			0x00 0x1F 0x38 0x3B 0x30 0x33 0x5c80 0x7600 0x8000
			0x00 0x20 0x34 0x37 0x30 0x33 0x5e00 0x7500 0x8000
			0x00 0x21 0x30 0x33 0x30 0x33 0x6100 0x7480 0x8000
			0x00 0x22 0x2C 0x2F 0x30 0x33 0x6400 0x7400 0x8000
			0x00 0x23 0x28 0x2B 0x30 0x33 0x6500 0x7300 0x8000
			0x00 0x24 0x24 0x27 0x30 0x33 0x6880 0x7400 0x8000
			0x00 0x25 0x20 0x23 0x30 0x33 0x6b00 0x7200 0x8000
			0x00 0x26 0x1C 0x1F 0x30 0x33 0x6e00 0x6f00 0x8000
			0x00 0x27 0x18 0x1B 0x30 0x33 0x7300 0x7080 0x8000
			0x00 0x28 0x14 0x17 0x30 0x33 0x7700 0x6d80 0x8000
			0x00 0x29 0x10 0x13 0x30 0x33 0x7c00 0x6d80 0x8000
			0x00 0x2A 0x0C 0x0F 0x30 0x33 0x8000 0x6c00 0x7e00
			0x00 0x2B 0x08 0x0B 0x30 0x33 0x8000 0x6700 0x7a00
			0x00 0x2C 0x04 0x07 0x30 0x33 0x8000 0x6100 0x7200
			0x00 0x2D 0x00 0x03 0x30 0x33 0x8000 0x5b00 0x6c00
			0x00 0x2E 0x38 0x3B 0x2C 0x2F 0x5c00 0x7880 0x8000
			0x00 0x2F 0x34 0x37 0x2C 0x2F 0x5f00 0x7700 0x8000
			0x00 0x30 0x30 0x33 0x2C 0x2F 0x6100 0x7700 0x8000
			0x00 0x31 0x2C 0x2F 0x2C 0x2F 0x6500 0x7680 0x8000
			0x00 0x32 0x28 0x2B 0x2C 0x2F 0x6700 0x7600 0x8000
			0x00 0x33 0x24 0x27 0x2C 0x2F 0x6a00 0x7500 0x8000
			0x00 0x34 0x20 0x23 0x2C 0x2F 0x6e00 0x7500 0x8000
			0x00 0x35 0x1C 0x1F 0x2C 0x2F 0x7180 0x7400 0x8000
			0x00 0x36 0x18 0x1B 0x2C 0x2F 0x7580 0x7300 0x8000
			0x00 0x37 0x14 0x17 0x2C 0x2F 0x7b00 0x7080 0x8000
			0x00 0x38 0x10 0x13 0x2C 0x2F 0x8000 0x7080 0x7f00
			0x00 0x39 0x0C 0x0F 0x2C 0x2F 0x8000 0x6b00 0x7a00
			0x00 0x3A 0x08 0x0B 0x2C 0x2F 0x8000 0x6500 0x7400
			0x00 0x3B 0x04 0x07 0x2C 0x2F 0x8000 0x6000 0x6d00
			0x00 0x3C 0x00 0x03 0x2C 0x2F 0x8000 0x5a00 0x6800
			0x00 0x3D 0x38 0x3B 0x28 0x2B 0x6000 0x7c00 0x8000
			0x00 0x3E 0x34 0x37 0x28 0x2B 0x6200 0x7b00 0x8000
			0x00 0x3F 0x30 0x33 0x28 0x2B 0x6600 0x7b00 0x8000
			0x00 0x40 0x2C 0x2F 0x28 0x2B 0x6900 0x7c00 0x8000
			0x00 0x41 0x28 0x2B 0x28 0x2B 0x6b80 0x7900 0x8000
			0x00 0x42 0x24 0x27 0x28 0x2B 0x6e00 0x7900 0x8000
			0x00 0x43 0x20 0x23 0x28 0x2B 0x7100 0x7780 0x8000
			0x00 0x44 0x1C 0x1F 0x28 0x2B 0x7500 0x7700 0x8000
			0x00 0x45 0x18 0x1B 0x28 0x2B 0x7a00 0x7600 0x8000
			0x00 0x46 0x14 0x17 0x28 0x2B 0x8000 0x7500 0x8000
			0x00 0x47 0x10 0x13 0x28 0x2B 0x8000 0x7000 0x7c00
			0x00 0x48 0x0C 0x0F 0x28 0x2B 0x8000 0x6b00 0x7800
			0x00 0x49 0x08 0x0B 0x28 0x2B 0x8000 0x6600 0x7200
			0x00 0x4A 0x04 0x07 0x28 0x2B 0x8000 0x6000 0x6c00
			0x00 0x4B 0x00 0x03 0x28 0x2B 0x8000 0x5900 0x6500
			0x00 0x4C 0x38 0x3B 0x24 0x27 0x6200 0x8000 0x8000
			0x00 0x4D 0x34 0x37 0x24 0x27 0x6500 0x7f00 0x8000
			0x00 0x4E 0x30 0x33 0x24 0x27 0x6800 0x7f00 0x8000
			0x00 0x4F 0x2C 0x2F 0x24 0x27 0x6b00 0x7e00 0x8000
			0x00 0x50 0x28 0x2B 0x24 0x27 0x6e00 0x7c80 0x8000
			0x00 0x51 0x24 0x27 0x24 0x27 0x7200 0x7d00 0x8000
			0x00 0x52 0x20 0x23 0x24 0x27 0x7500 0x7a00 0x8000
			0x00 0x53 0x1C 0x1F 0x24 0x27 0x7900 0x7a00 0x8000
			0x00 0x54 0x18 0x1B 0x24 0x27 0x7e00 0x7a00 0x8000
			0x00 0x55 0x14 0x17 0x24 0x27 0x8000 0x7300 0x7c00
			0x00 0x56 0x10 0x13 0x24 0x27 0x8000 0x6e00 0x7800
			0x00 0x57 0x0C 0x0F 0x24 0x27 0x8000 0x6900 0x7300
			0x00 0x58 0x08 0x0B 0x24 0x27 0x8000 0x6400 0x6d00
			0x00 0x59 0x04 0x07 0x24 0x27 0x8000 0x5e00 0x6800
			0x00 0x5A 0x00 0x03 0x24 0x27 0x8000 0x5900 0x6300
			0x00 0x5B 0x38 0x3B 0x20 0x23 0x6200 0x8000 0x7d00
			0x00 0x5C 0x34 0x37 0x20 0x23 0x6600 0x8000 0x7e00
			0x00 0x5D 0x30 0x33 0x20 0x23 0x6a00 0x8000 0x7f00
			0x00 0x5E 0x2C 0x2F 0x20 0x23 0x6d00 0x8000 0x7f00
			0x00 0x5F 0x28 0x2B 0x20 0x23 0x7100 0x8000 0x8000
			0x00 0x60 0x24 0x27 0x20 0x23 0x7400 0x7f00 0x8000
			0x00 0x61 0x20 0x23 0x20 0x23 0x7700 0x7e80 0x8000
			0x00 0x62 0x1C 0x1F 0x20 0x23 0x7b00 0x7d00 0x8000
			0x00 0x63 0x18 0x1B 0x20 0x23 0x7f00 0x7c00 0x8000
			0x00 0x64 0x14 0x17 0x20 0x23 0x8000 0x7500 0x7b00
			0x00 0x65 0x10 0x13 0x20 0x23 0x8000 0x7000 0x7600
			0x00 0x66 0x0C 0x0F 0x20 0x23 0x8000 0x6a00 0x7100
			0x00 0x67 0x08 0x0B 0x20 0x23 0x8000 0x6400 0x6b00
			0x00 0x68 0x04 0x07 0x20 0x23 0x8000 0x5e00 0x6600
			0x00 0x69 0x00 0x03 0x20 0x23 0x8000 0x5800 0x6000
			0x00 0x6A 0x38 0x3B 0x1C 0x1F 0x6300 0x8000 0x7a00
			0x00 0x6B 0x34 0x37 0x1C 0x1F 0x6600 0x8000 0x7b00
			0x00 0x6C 0x30 0x33 0x1C 0x1F 0x6a00 0x8000 0x7c00
			0x00 0x6D 0x2C 0x2F 0x1C 0x1F 0x6e00 0x8000 0x7d00
			0x00 0x6E 0x28 0x2B 0x1C 0x1F 0x7200 0x8000 0x7e00
			0x00 0x6F 0x24 0x27 0x1C 0x1F 0x7600 0x8000 0x7e00
			0x00 0x70 0x20 0x23 0x1C 0x1F 0x7a00 0x8000 0x7f00
			0x00 0x71 0x18 0x1B 0x1C 0x1F 0x8000 0x7c00 0x7c00
			0x00 0x72 0x14 0x17 0x1C 0x1F 0x8000 0x7400 0x7780
			0x00 0x73 0x10 0x13 0x1C 0x1F 0x8000 0x6f00 0x7300
			0x00 0x74 0x0C 0x0F 0x1C 0x1F 0x8000 0x6900 0x6e00
			0x00 0x75 0x08 0x0B 0x1C 0x1F 0x8000 0x6300 0x6800
			0x00 0x76 0x04 0x07 0x1C 0x1F 0x8000 0x5d00 0x6280
			0x00 0x77 0x00 0x03 0x1C 0x1F 0x8000 0x5800 0x5d00
			0x00 0x78 0x38 0x3B 0x18 0x1B 0x6300 0x8000 0x7800
			0x00 0x79 0x34 0x37 0x18 0x1B 0x6700 0x8000 0x7900
			0x00 0x7A 0x30 0x33 0x18 0x1B 0x6a00 0x8000 0x7900
			0x00 0x7B 0x2C 0x2F 0x18 0x1B 0x6e00 0x8000 0x7b00
			0x00 0x7C 0x28 0x2B 0x18 0x1B 0x7180 0x8000 0x7c00
			0x00 0x7D 0x24 0x27 0x18 0x1B 0x7500 0x8000 0x7b00
			0x00 0x7E 0x20 0x23 0x18 0x1B 0x7a00 0x8000 0x7c80
			0x00 0x7F 0x1C 0x1F 0x18 0x1B 0x8000 0x8000 0x7e00
			0x00 0x80 0x18 0x1B 0x18 0x1B 0x8000 0x7a00 0x7900
			0x00 0x81 0x14 0x17 0x18 0x1B 0x8000 0x7400 0x7500
			0x00 0x82 0x10 0x13 0x18 0x1B 0x8000 0x6e00 0x6f00
			0x00 0x83 0x0C 0x0F 0x18 0x1B 0x8000 0x6900 0x6b00
			0x00 0x84 0x08 0x0B 0x18 0x1B 0x8000 0x6200 0x6500
			0x00 0x85 0x04 0x07 0x18 0x1B 0x8000 0x5d00 0x6000
			0x00 0x86 0x00 0x03 0x18 0x1B 0x8000 0x5700 0x5b00
			0x00 0x87 0x38 0x3B 0x14 0x17 0x6300 0x8000 0x7580
			0x00 0x88 0x34 0x37 0x14 0x17 0x6700 0x8000 0x7680
			0x00 0x89 0x30 0x33 0x14 0x17 0x6a00 0x8000 0x7780
			0x00 0x8A 0x2C 0x2F 0x14 0x17 0x6d00 0x8000 0x7800
			0x00 0x8B 0x28 0x2B 0x14 0x17 0x7100 0x8000 0x7800
			0x00 0x8C 0x24 0x27 0x14 0x17 0x7500 0x8000 0x7980
			0x00 0x8D 0x20 0x23 0x14 0x17 0x7a00 0x8000 0x7a00
			0x00 0x8E 0x1C 0x1F 0x14 0x17 0x7f00 0x8000 0x7a80
			0x00 0x8F 0x18 0x1B 0x14 0x17 0x8000 0x7b00 0x7700
			0x00 0x90 0x14 0x17 0x14 0x17 0x8000 0x7300 0x7100
			0x00 0x91 0x10 0x13 0x14 0x17 0x8000 0x6d00 0x6d00
			0x00 0x92 0x0C 0x0F 0x14 0x17 0x8000 0x6800 0x6900
			0x00 0x93 0x08 0x0B 0x14 0x17 0x8000 0x6200 0x6300
			0x00 0x94 0x04 0x07 0x14 0x17 0x8000 0x5c00 0x5d00
			0x00 0x95 0x00 0x03 0x14 0x17 0x8000 0x5600 0x5900
			0x00 0x96 0x38 0x3B 0x10 0x13 0x6300 0x8000 0x7300
			0x00 0x97 0x34 0x37 0x10 0x13 0x6600 0x8000 0x7400
			0x00 0x98 0x30 0x33 0x10 0x13 0x6a00 0x8000 0x7500
			0x00 0x99 0x2C 0x2F 0x10 0x13 0x6e00 0x8000 0x7600
			0x00 0x9A 0x28 0x2B 0x10 0x13 0x7100 0x8000 0x7600
			0x00 0x9B 0x24 0x27 0x10 0x13 0x7500 0x8000 0x7700
			0x00 0x9C 0x20 0x23 0x10 0x13 0x7980 0x8000 0x7800
			0x00 0x9D 0x1C 0x1F 0x10 0x13 0x7f00 0x8000 0x7800
			0x00 0x9E 0x18 0x1B 0x10 0x13 0x8000 0x7b00 0x7500
			0x00 0x9F 0x14 0x17 0x10 0x13 0x8000 0x7300 0x6f00
			0x00 0xA0 0x10 0x13 0x10 0x13 0x8000 0x6d00 0x6b00
			0x00 0xA1 0x0C 0x0F 0x10 0x13 0x8000 0x6800 0x6600
			0x00 0xA2 0x08 0x0B 0x10 0x13 0x8000 0x6200 0x6000
			0x00 0xA3 0x04 0x07 0x10 0x13 0x8000 0x5b00 0x5b00
			0x00 0xA4 0x00 0x03 0x10 0x13 0x8000 0x5600 0x5700
			0x00 0xA5 0x38 0x3B 0x0C 0x0F 0x6200 0x8000 0x7000
			0x00 0xA6 0x34 0x37 0x0C 0x0F 0x6700 0x8000 0x7100
			0x00 0xA7 0x30 0x33 0x0C 0x0F 0x6a00 0x8000 0x7200
			0x00 0xA8 0x2C 0x2F 0x0C 0x0F 0x6d00 0x8000 0x7300
			0x00 0xA9 0x28 0x2B 0x0C 0x0F 0x7100 0x8000 0x7400
			0x00 0xAA 0x24 0x27 0x0C 0x0F 0x7500 0x8000 0x7480
			0x00 0xAB 0x20 0x23 0x0C 0x0F 0x7900 0x8000 0x7500
			0x00 0xAC 0x1C 0x1F 0x0C 0x0F 0x7f00 0x8000 0x7600
			0x00 0xAD 0x18 0x1B 0x0C 0x0F 0x8000 0x7b00 0x7200
			0x00 0xAE 0x14 0x17 0x0C 0x0F 0x8000 0x7300 0x6d00
			0x00 0xAF 0x10 0x13 0x0C 0x0F 0x8000 0x6d00 0x6800
			0x00 0xB0 0x0C 0x0F 0x0C 0x0F 0x8000 0x6800 0x6400
			0x00 0xB1 0x08 0x0B 0x0C 0x0F 0x8000 0x6100 0x5d00
			0x00 0xB2 0x04 0x07 0x0C 0x0F 0x8000 0x5b00 0x5900
			0x00 0xB3 0x00 0x03 0x0C 0x0F 0x8000 0x5600 0x5480
			0x00 0xB4 0x38 0x3B 0x08 0x0B 0x6200 0x8000 0x6e00
			0x00 0xB5 0x34 0x37 0x08 0x0B 0x6600 0x8000 0x6e00
			0x00 0xB6 0x30 0x33 0x08 0x0B 0x6900 0x8000 0x6f00
			0x00 0xB7 0x2C 0x2F 0x08 0x0B 0x6d00 0x8000 0x7000
			0x00 0xB8 0x28 0x2B 0x08 0x0B 0x7100 0x8000 0x7200
			0x00 0xB9 0x24 0x27 0x08 0x0B 0x7500 0x8000 0x7200
			0x00 0xBA 0x20 0x23 0x08 0x0B 0x7a00 0x8000 0x7200
			0x00 0xBB 0x1C 0x1F 0x08 0x0B 0x7f00 0x8000 0x7300
			0x00 0xBC 0x18 0x1B 0x08 0x0B 0x8000 0x7b00 0x7000
			0x00 0xBD 0x14 0x17 0x08 0x0B 0x8000 0x7200 0x6a00
			0x00 0xBE 0x10 0x13 0x08 0x0B 0x8000 0x6c00 0x6500
			0x00 0xBF 0x0C 0x0F 0x08 0x0B 0x8000 0x6600 0x6000
			0x00 0xC0 0x08 0x0B 0x08 0x0B 0x8000 0x6000 0x5b00
			0x00 0xC1 0x04 0x07 0x08 0x0B 0x8000 0x5b00 0x5700
			0x00 0xC2 0x00 0x03 0x08 0x0B 0x8000 0x5500 0x5100
			0x00 0xC3 0x38 0x3B 0x04 0x07 0x6200 0x8000 0x6b00
			0x00 0xC4 0x34 0x37 0x04 0x07 0x6500 0x8000 0x6c00
			0x00 0xC5 0x30 0x33 0x04 0x07 0x6800 0x8000 0x6d80
			0x00 0xC6 0x2C 0x2F 0x04 0x07 0x6c00 0x8000 0x6e00
			0x00 0xC7 0x28 0x2B 0x04 0x07 0x7000 0x8000 0x6e00
			0x00 0xC8 0x24 0x27 0x04 0x07 0x7400 0x8000 0x6f00
			0x00 0xC9 0x20 0x23 0x04 0x07 0x7800 0x8000 0x7000
			0x00 0xCA 0x1C 0x1F 0x04 0x07 0x7e00 0x8000 0x7000
			0x00 0xCB 0x18 0x1B 0x04 0x07 0x8000 0x7a80 0x6b80
			0x00 0xCC 0x14 0x17 0x04 0x07 0x8000 0x7400 0x6780
			0x00 0xCD 0x10 0x13 0x04 0x07 0x8000 0x6e00 0x6380
			0x00 0xCE 0x0C 0x0F 0x04 0x07 0x8000 0x6700 0x5e00
			0x00 0xCF 0x08 0x0B 0x04 0x07 0x8000 0x6180 0x5980
			0x00 0xD0 0x04 0x07 0x04 0x07 0x8000 0x5b00 0x5500
			0x00 0xD1 0x00 0x03 0x04 0x07 0x8000 0x5500 0x5100
			0x00 0xD2 0x38 0x3B 0x00 0x03 0x6100 0x8000 0x6900
			0x00 0xD3 0x34 0x37 0x00 0x03 0x6400 0x8000 0x6a00
			0x00 0xD4 0x30 0x33 0x00 0x03 0x6800 0x8000 0x6b00
			0x00 0xD5 0x2C 0x2F 0x00 0x03 0x6c00 0x8000 0x6b80
			0x00 0xD6 0x28 0x2B 0x00 0x03 0x6f00 0x8000 0x6c00
			0x00 0xD7 0x24 0x27 0x00 0x03 0x7300 0x8000 0x6d00
			0x00 0xD8 0x20 0x23 0x00 0x03 0x7900 0x8000 0x6d00
			0x00 0xD9 0x1C 0x1F 0x00 0x03 0x7f00 0x8000 0x6e00
			0x00 0xDA 0x18 0x1B 0x00 0x03 0x8000 0x7b00 0x6a80
			0x00 0xDB 0x14 0x17 0x00 0x03 0x8000 0x7400 0x6580
			0x00 0xDC 0x10 0x13 0x00 0x03 0x8000 0x6d00 0x6180
			0x00 0xDD 0x0C 0x0F 0x00 0x03 0x8000 0x6900 0x5e00
			0x00 0xDE 0x08 0x0B 0x00 0x03 0x8000 0x6200 0x5800
			0x00 0xDF 0x04 0x07 0x00 0x03 0x8000 0x5a00 0x5200
			0x00 0xE0 0x00 0x03 0x00 0x03 0x8000 0x5400 0x4d00
			0xFF 0x00 0x00 0x3B 0x00 0x3B 0x8000 0x8000 0x8000>;

		somc,chenge-fps-command = [15 01 00 00 00 00 02 FF 24
				15 01 00 00 00 00 02 92 92
				15 01 00 00 00 00 02 FF 10
				39 01 00 00 00 00 03 44 03 00];
		somc,chenge-fps-default = <0x92>;
		somc,display-clock = <17330000>;
		somc,driver-ic-vbp = <48>;
		somc,driver-ic-vfp = <6>;
		somc,chenge-fps-cmds-num = <1>;
		somc,chenge-fps-payload-num = <1>;

		somc,chenge-wait-update = <0>;
		somc,chenge-wait-on = <0 0>;
		somc,chenge-wait-off = <0 0>;
		somc,chenge-wait-cmds-num = <0 0>;
		somc,fps-threshold = <47400>;
		somc,te-c-update = <1>;
		somc,te-c-mode-60fps = <0x03 0x00>;
		somc,te-c-mode-45fps = <0x04 0xFF>;
		somc,te-c-cmds-num = <3>;
		somc,te-c-payload-num = <1>;
	};

	dsi_default_gpio_0: somc,default_panel_0 {
		qcom,mdss-dsi-panel-name = "default video 0";
		qcom,mdss-dsi-panel-controller = <&mdss_dsi0>;
		qcom,mdss-dsi-panel-type = "dsi_video_mode";
		qcom,mdss-dsi-panel-destination = "display_1";
		qcom,mdss-dsi-panel-framerate = <60>;
		qcom,mdss-dsi-virtual-channel-id = <0>;
		qcom,mdss-dsi-stream = <0>;
		qcom,mdss-dsi-panel-width = <1080>;
		qcom,mdss-dsi-panel-height = <1920>;
		qcom,mdss-dsi-h-front-porch = <136>;
		qcom,mdss-dsi-h-back-porch = <20>;
		qcom,mdss-dsi-h-pulse-width = <60>;
		qcom,mdss-dsi-h-sync-skew = <0>;
		qcom,mdss-dsi-v-back-porch = <3>;
		qcom,mdss-dsi-v-front-porch = <4>;
		qcom,mdss-dsi-v-pulse-width = <2>;
		qcom,mdss-dsi-h-left-border = <0>;
		qcom,mdss-dsi-h-right-border = <0>;
		qcom,mdss-dsi-v-top-border = <0>;
		qcom,mdss-dsi-v-bottom-border = <0>;
		qcom,mdss-dsi-bpp = <24>;
		qcom,mdss-dsi-underflow-color = <0x0>;
		qcom,mdss-dsi-border-color = <0>;
		somc,mdss-dsi-init-command = [15 01 00 00 00 00 02 BB 03
				39 01 00 00 00 00 06 3B 03 05 04 50 88
				15 01 00 00 00 00 02 FF 24
				15 01 00 00 00 00 02 FB 01
				15 01 00 00 00 00 02 C4 9A
				15 01 00 00 00 00 02 FF 10];
		qcom,mdss-dsi-on-command = [05 01 00 00 96 00 01 11
				05 01 00 00 28 00 01 29];
		qcom,mdss-dsi-off-command = [15 01 00 00 00 00 02 FF 10
				05 01 00 00 14 00 01 28
				05 01 00 00 50 00 01 10];
		qcom,mdss-dsi-on-command-state = "dsi_lp_mode";
		qcom,mdss-dsi-off-command-state = "dsi_hs_mode";
		qcom,mdss-dsi-h-sync-pulse = <1>;
		qcom,mdss-dsi-traffic-mode = "non_burst_sync_event";
		qcom,mdss-dsi-bllp-eof-power-mode;
		qcom,mdss-dsi-bllp-power-mode;
		qcom,mdss-dsi-lane-0-state;
		qcom,mdss-dsi-lane-1-state;
		qcom,mdss-dsi-lane-2-state;
		qcom,mdss-dsi-lane-3-state;
		qcom,mdss-dsi-panel-timings = [E6 38 26 00 68 6E 2A 3C 2C 03 04 00];
		qcom,mdss-dsi-lp11-init;
		qcom,mdss-dsi-t-clk-post = <0x02>;
		qcom,mdss-dsi-t-clk-pre = <0x2B>;
		qcom,mdss-dsi-bl-min-level = <1>;
		qcom,mdss-dsi-bl-max-level = <4095>;
		qcom,mdss-brightness-max-level = <4095>;
		qcom,mdss-dsi-dma-trigger = "trigger_sw";
		qcom,mdss-dsi-mdp-trigger = "none";
		qcom,mdss-dsi-bl-pmic-control-type = "bl_ctrl_wled";
		qcom,mdss-dsi-pan-enable-dynamic-fps;
		qcom,mdss-dsi-pan-fps-update = "dfps_suspend_resume_mode";
		qcom,cont-splash-enabled;

		somc,driver-ic = <0>;
		somc,dric-gpio = <&msmgpio 26 0>;
		somc,touch-reset-gpio = <&msmgpio 85 0>;
		somc,mul-channel-scaling = <3>;
		somc,mdss-phy-size-mm = <64 114>;
		somc,mdss-dsi-lane-config = [00 c2 ef 00 00 00 00 01 ff
				00 c2 ef 00 00 00 00 01 ff
				00 c2 ef 00 00 00 00 01 ff
				00 c2 ef 00 00 00 00 01 ff
				00 02 45 00 00 00 00 01 97];
		somc,mdss-dsi-disp-on-in-hs = <1>;
		somc,mdss-dsi-wait-time-before-on-cmd = <150>;
		somc,lcd-id = <0>;
		somc,lcd-id-adc = <0 0x7fffffff>;
		somc,disp-en-on-pre = <200>;
		somc,disp-en-on-post = <10>;
		somc,pw-on-rst-seq = <1 1>, <0 1>, <1 20>;
		somc,disp-en-off-post = <200>;
		somc,pw-off-rst-seq = <0 5>;
		somc,pw-down-period = <100>;
	};

	dsi_default_gpio_1: somc,default_panel_1 {
		qcom,mdss-dsi-panel-name = "default video 1";
		qcom,mdss-dsi-panel-controller = <&mdss_dsi0>;
		qcom,mdss-dsi-panel-type = "dsi_video_mode";
		qcom,mdss-dsi-panel-destination = "display_1";
		qcom,mdss-dsi-panel-framerate = <60>;
		qcom,mdss-dsi-virtual-channel-id = <0>;
		qcom,mdss-dsi-stream = <0>;
		qcom,mdss-dsi-panel-width = <1080>;
		qcom,mdss-dsi-panel-height = <1920>;
		qcom,mdss-dsi-h-front-porch = <136>;
		qcom,mdss-dsi-h-back-porch = <20>;
		qcom,mdss-dsi-h-pulse-width = <60>;
		qcom,mdss-dsi-h-sync-skew = <0>;
		qcom,mdss-dsi-v-back-porch = <3>;
		qcom,mdss-dsi-v-front-porch = <4>;
		qcom,mdss-dsi-v-pulse-width = <2>;
		qcom,mdss-dsi-h-left-border = <0>;
		qcom,mdss-dsi-h-right-border = <0>;
		qcom,mdss-dsi-v-top-border = <0>;
		qcom,mdss-dsi-v-bottom-border = <0>;
		qcom,mdss-dsi-bpp = <24>;
		qcom,mdss-dsi-underflow-color = <0x0>;
		qcom,mdss-dsi-border-color = <0>;
		somc,mdss-dsi-init-command = [15 01 00 00 00 00 02 BB 03
				39 01 00 00 00 00 06 3B 03 05 04 50 88
				15 01 00 00 00 00 02 FF 24
				15 01 00 00 00 00 02 FB 01
				15 01 00 00 00 00 02 C4 9A
				15 01 00 00 00 00 02 FF 10];
		qcom,mdss-dsi-on-command = [05 01 00 00 96 00 01 11
				05 01 00 00 28 00 01 29];
		qcom,mdss-dsi-off-command = [15 01 00 00 00 00 02 FF 10
				05 01 00 00 14 00 01 28
				05 01 00 00 50 00 01 10];
		qcom,mdss-dsi-on-command-state = "dsi_lp_mode";
		qcom,mdss-dsi-off-command-state = "dsi_hs_mode";
		qcom,mdss-dsi-h-sync-pulse = <1>;
		qcom,mdss-dsi-traffic-mode = "non_burst_sync_event";
		qcom,mdss-dsi-bllp-eof-power-mode;
		qcom,mdss-dsi-bllp-power-mode;
		qcom,mdss-dsi-lane-0-state;
		qcom,mdss-dsi-lane-1-state;
		qcom,mdss-dsi-lane-2-state;
		qcom,mdss-dsi-lane-3-state;
		qcom,mdss-dsi-panel-timings = [E6 38 26 00 68 6E 2A 3C 2C 03 04 00];
		qcom,mdss-dsi-lp11-init;
		qcom,mdss-dsi-t-clk-post = <0x02>;
		qcom,mdss-dsi-t-clk-pre = <0x2B>;
		qcom,mdss-dsi-bl-min-level = <1>;
		qcom,mdss-dsi-bl-max-level = <4095>;
		qcom,mdss-brightness-max-level = <4095>;
		qcom,mdss-dsi-dma-trigger = "trigger_sw";
		qcom,mdss-dsi-mdp-trigger = "none";
		qcom,mdss-dsi-bl-pmic-control-type = "bl_ctrl_wled";
		qcom,mdss-dsi-pan-enable-dynamic-fps;
		qcom,mdss-dsi-pan-fps-update = "dfps_suspend_resume_mode";
		qcom,cont-splash-enabled;

		somc,driver-ic = <0>;
		somc,dric-gpio = <&msmgpio 26 0>;
		somc,touch-reset-gpio = <&msmgpio 85 0>;
		somc,mul-channel-scaling = <3>;
		somc,mdss-phy-size-mm = <64 114>;
		somc,mdss-dsi-lane-config = [00 c2 ef 00 00 00 00 01 ff
				00 c2 ef 00 00 00 00 01 ff
				00 c2 ef 00 00 00 00 01 ff
				00 c2 ef 00 00 00 00 01 ff
				00 02 45 00 00 00 00 01 97];
		somc,mdss-dsi-disp-on-in-hs = <1>;
		somc,mdss-dsi-wait-time-before-on-cmd = <150>;
		somc,lcd-id = <1>;
		somc,lcd-id-adc = <0 0x7fffffff>;
		somc,disp-en-on-pre = <200>;
		somc,disp-en-on-post = <10>;
		somc,pw-on-rst-seq = <1 1>, <0 1>, <1 20>;
		somc,disp-en-off-post = <200>;
		somc,pw-off-rst-seq = <0 5>;
		somc,pw-down-period = <100>;
	};
};
